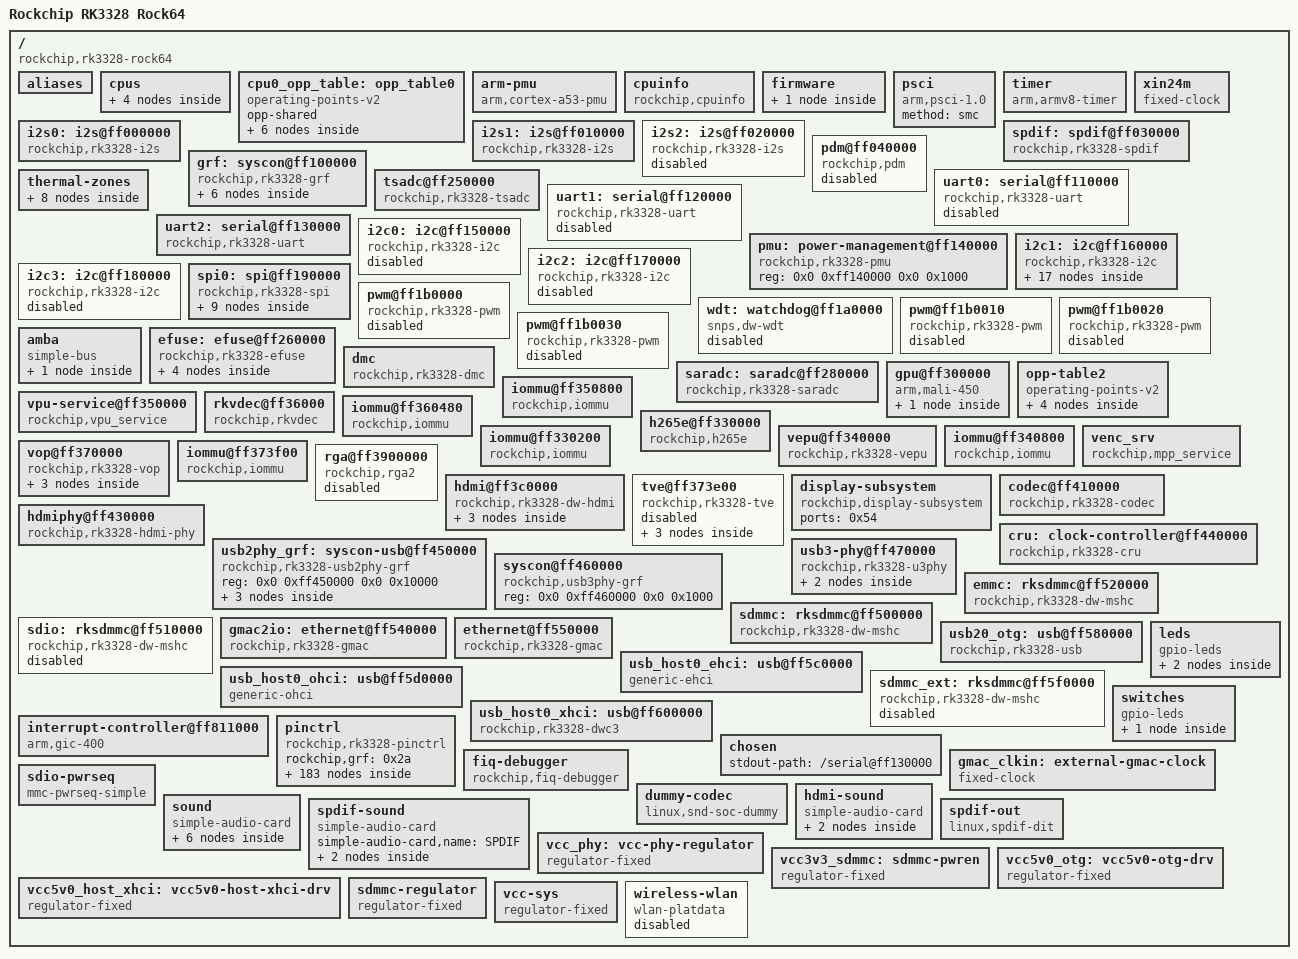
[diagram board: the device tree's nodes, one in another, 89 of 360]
/*
 * (C) Copyright 2017 Rock64
 *
 * SPDX-License-Identifier:     GPL-2.0+
 */

/dts-v1/;

#include <dt-bindings/clock/rk3328-cru.h>
#include <dt-bindings/gpio/gpio.h>
#include <dt-bindings/interrupt-controller/arm-gic.h>
#include <dt-bindings/interrupt-controller/irq.h>
#include <dt-bindings/pinctrl/rockchip.h>

/ {
	compatible = "rockchip,rk3328-rock64", "rockchip,rk3328";
	interrupt-parent = <0x1>;
	#address-cells = <0x2>;
	#size-cells = <0x2>;
	model = "Rockchip RK3328 Rock64";

	aliases {
		serial0 = &uart0;
		serial1 = &uart1;
		serial2 = &uart2;
		i2c0 = &i2c0;
		i2c1 = &i2c1;
		i2c2 = &i2c2;
		i2c3 = &i2c3;
		mmc0 = &emmc;
		mmc1 = &sdmmc;
		mmc2 = &sdmmc_ext;
		spi0 = &spi0;		
		ethernet0 = &gmac2io;
		ethernet1 = "/ethernet@ff550000";		
	};

	cpus {
		#address-cells = <2>;
		#size-cells = <0>;

		cpu0: cpu@0 {
			device_type = "cpu";
			compatible = "arm,cortex-a53", "arm,armv8";
			reg = <0x0 0x0>;
			enable-method = "psci";
			clocks = <&cru ARMCLK>;
			#cooling-cells = <0x2>;			
            dynamic-power-coefficient = <0x78>;
			operating-points-v2 = <&cpu0_opp_table>;			
			cpu-supply = <0x4>;
		};
		cpu1: cpu@1 {
			device_type = "cpu";
			compatible = "arm,cortex-a53", "arm,armv8";
			reg = <0x0 0x1>;
			enable-method = "psci";
			operating-points-v2 = <&cpu0_opp_table>;			
		};
		cpu2: cpu@2 {
			device_type = "cpu";
			compatible = "arm,cortex-a53", "arm,armv8";
			reg = <0x0 0x2>;
			enable-method = "psci";
			operating-points-v2 = <&cpu0_opp_table>;			
		};
		cpu3: cpu@3 {
			device_type = "cpu";
			compatible = "arm,cortex-a53", "arm,armv8";
			reg = <0x0 0x3>;
			enable-method = "psci";
			operating-points-v2 = <&cpu0_opp_table>;			
		};
	};

	cpu0_opp_table: opp_table0 {
		compatible = "operating-points-v2";
		opp-shared;

		opp@408000000 {
			opp-hz = /bits/ 64 <408000000>;
			opp-microvolt = <950000>;
			clock-latency-ns = <40000>;
			opp-suspend;
		};
		opp@600000000 {
			opp-hz = /bits/ 64 <600000000>;
			opp-microvolt = <950000>;
			clock-latency-ns = <40000>;
		};
		opp@816000000 {
			opp-hz = /bits/ 64 <816000000>;
			opp-microvolt = <1000000>;
			clock-latency-ns = <40000>;
		};
		opp@1008000000 {
			opp-hz = /bits/ 64 <1008000000>;
			opp-microvolt = <1100000>;
			clock-latency-ns = <40000>;
		};
		opp@1200000000 {
			opp-hz = /bits/ 64 <1200000000>;
			opp-microvolt = <1225000>;
			clock-latency-ns = <40000>;
		};
		opp@1296000000 {
			opp-hz = /bits/ 64 <1296000000>;
			opp-microvolt = <1300000>;
			clock-latency-ns = <40000>;
		};
	};

	arm-pmu {
		compatible = "arm,cortex-a53-pmu";
		interrupts = <GIC_SPI 100 IRQ_TYPE_LEVEL_HIGH>,
			     <GIC_SPI 101 IRQ_TYPE_LEVEL_HIGH>,
			     <GIC_SPI 102 IRQ_TYPE_LEVEL_HIGH>,
			     <GIC_SPI 103 IRQ_TYPE_LEVEL_HIGH>;
		interrupt-affinity = <&cpu0>, <&cpu1>, <&cpu2>, <&cpu3>;
	};

	cpuinfo {
		compatible = "rockchip,cpuinfo";
		nvmem-cells = <0x9 0xa>;
		nvmem-cell-names = "id", "cpu-version";
	};

	firmware {

		optee {
			compatible = "linaro,optee-tz";
			method = "smc";
		};
	};

	psci {
		compatible = "arm,psci-1.0";
		method = "smc";
	};

	timer {
		compatible = "arm,armv8-timer";
		interrupts = <GIC_PPI 13 (GIC_CPU_MASK_SIMPLE(4) | IRQ_TYPE_LEVEL_LOW)>,
			     <GIC_PPI 14 (GIC_CPU_MASK_SIMPLE(4) | IRQ_TYPE_LEVEL_LOW)>,
			     <GIC_PPI 11 (GIC_CPU_MASK_SIMPLE(4) | IRQ_TYPE_LEVEL_LOW)>,
			     <GIC_PPI 10 (GIC_CPU_MASK_SIMPLE(4) | IRQ_TYPE_LEVEL_LOW)>;
	};

	xin24m: xin24m {
		compatible = "fixed-clock";
		#clock-cells = <0>;
		clock-frequency = <24000000>;
		clock-output-names = "xin24m";
	};

	i2s0: i2s@ff000000 {
		compatible = "rockchip,rk3328-i2s", "rockchip,rk3066-i2s";
		reg = <0x0 0xff000000 0x0 0x1000>;
		interrupts = <GIC_SPI 26 IRQ_TYPE_LEVEL_HIGH>;
		clocks = <&cru SCLK_I2S0>, <&cru HCLK_I2S0_8CH>;
		clock-names = "i2s_clk", "i2s_hclk";
		dmas = <&dmac 11>, <&dmac 12>;
		#dma-cells = <2>;
		dma-names = "tx", "rx";
        status = "okay";
        #sound-dai-cells = <0x0>;
        rockchip,bclk-fs = <0x80>;

	};

	i2s1: i2s@ff010000 {
		compatible = "rockchip,rk3328-i2s", "rockchip,rk3066-i2s";
		reg = <0x0 0xff010000 0x0 0x1000>;
		interrupts = <GIC_SPI 27 IRQ_TYPE_LEVEL_HIGH>;
		clocks = <&cru SCLK_I2S1>, <&cru HCLK_I2S1_8CH>;
		clock-names = "i2s_clk", "i2s_hclk";
		dmas = <&dmac 14>, <&dmac 15>;
		#dma-cells = <2>;
		dma-names = "tx", "rx";
		status = "okay";
        pinctrl-names = "default";
        pinctrl-0 = <0xc 0xd 0xe 0xf 0x10 0x11 0x12 0x13 0x14>;
        #sound-dai-cells = <0x0>;

	};

	i2s2: i2s@ff020000 {
		compatible = "rockchip,rk3328-i2s", "rockchip,rk3066-i2s";
		reg = <0x0 0xff020000 0x0 0x1000>;
		interrupts = <GIC_SPI 28 IRQ_TYPE_LEVEL_HIGH>;
		clocks = <&cru SCLK_I2S2>, <&cru HCLK_I2S2_2CH>;
		clock-names = "i2s_clk", "i2s_hclk";
		dmas = <&dmac 0>, <&dmac 1>;
		#dma-cells = <2>;
		dma-names = "tx", "rx";
		pinctrl-names = "default", "sleep";
		pinctrl-0 = <&i2s2m0_mclk
			     &i2s2m0_sclk
			     &i2s2m0_lrcktx
			     &i2s2m0_lrckrx
			     &i2s2m0_sdo
			     &i2s2m0_sdi>;
		pinctrl-1 = <&i2s2m0_sleep>;
		status = "disabled";
	};

	spdif: spdif@ff030000 {
		compatible = "rockchip,rk3328-spdif";
		reg = <0x0 0xff030000 0x0 0x1000>;
		interrupts = <GIC_SPI 29 IRQ_TYPE_LEVEL_HIGH>;
		clocks = <&cru SCLK_SPDIF>, <&cru HCLK_SPDIF_8CH>;
		clock-names = "mclk", "hclk";
		dmas = <&dmac 10>;
		#dma-cells = <1>;
		dma-names = "tx";
		pinctrl-names = "default";
		pinctrl-0 = <&spdifm2_tx>;
		status = "okay";
        #sound-dai-cells = <0x0>;

	};

	pdm@ff040000 {
		compatible = "rockchip,pdm";
		reg = <0x0 0xff040000 0x0 0x1000>;
		clocks = <0x2 0x3d 0x2 0x152>;
		clock-names = "pdm_clk", "pdm_hclk";
		dmas = <0xb 0x10>;
		#dma-cells = <0x1>;
		dma-names = "rx";
		pinctrl-names = "default", "sleep";
		pinctrl-0 = <0x1d 0x1e 0x1f 0x20 0x21 0x22>;
		pinctrl-1 = <0x23>;
		status = "disabled";
	};

	grf: syscon@ff100000 {
		u-boot,dm-pre-reloc;
		compatible = "rockchip,rk3328-grf", "syscon", "simple-mfd";
		reg = <0x0 0xff100000 0x0 0x1000>;
		#address-cells = <0x1>;
		#size-cells = <0x1>;
		linux,phandle = <0x2a>;
		phandle = <0x2a>;

		io-domains {
			compatible = "rockchip,rk3328-io-voltage-domain";
			status = "okay";
			vccio1-supply = <0x24>;
			vccio2-supply = <0x25>;
			vccio3-supply = <0x24>;
			vccio4-supply = <0x26>;
			vccio5-supply = <0x24>;
			vccio6-supply = <0x24>;
			pmuio-supply = <0x24>;
		};

		power-controller {
			compatible = "rockchip,rk3328-power-controller";
			#power-domain-cells = <0x1>;
			#address-cells = <0x1>;
			#size-cells = <0x0>;
			status = "okay";
			linux,phandle = <0x45>;
			phandle = <0x45>;

			pd_hevc@6 {
				reg = <0x6>;
			};

			pd_video@5 {
				reg = <0x5>;
			};

			pd_vpu@8 {
				reg = <0x8>;
			};
		};

		reboot-mode {
			compatible = "syscon-reboot-mode";
			offset = <0x5c8>;
			mode-bootloader = <0x5242c301>;
			mode-charge = <0x5242c30b>;
			mode-fastboot = <0x5242c309>;
			mode-loader = <0x5242c301>;
			mode-normal = <0x5242c300>;
			mode-recovery = <0x5242c303>;
			mode-ums = <0x5242c30c>;
		};
	};

	thermal-zones {

		soc-thermal {
			polling-delay-passive = <0x14>;
			polling-delay = <0x3e8>;
			sustainable-power = <0x3e8>;
			thermal-sensors = <0x27 0x0>;

			trips {

				trip-point@0 {
					temperature = <0x11170>;
					hysteresis = <0x7d0>;
					type = "passive";
				};

				trip-point@1 {
					temperature = <0x14c08>;
					hysteresis = <0x7d0>;
					type = "passive";
					linux,phandle = <0x28>;
					phandle = <0x28>;
				};

				soc-crit {
					temperature = <0x17318>;
					hysteresis = <0x7d0>;
					type = "critical";
				};
			};

			cooling-maps {

				map0 {
					trip = <0x28>;
					cooling-device = <0x5 0xffffffff 0xffffffff>;
					contribution = <0x1000>;
				};

				map1 {
					trip = <0x28>;
					cooling-device = <0x29 0xffffffff 0xffffffff>;
					contribution = <0x1000>;
				};
			};
		};
	};

	tsadc@ff250000 {
		compatible = "rockchip,rk3328-tsadc";
		reg = <0x0 0xff250000 0x0 0x100>;
		interrupts = <0x0 0x3a 0x4 0x0>;
		rockchip,grf = <0x2a>;
		clocks = <0x2 0x24 0x2 0xd5>;
		clock-names = "tsadc", "apb_pclk";
		assigned-clocks = <0x2 0x24>;
		assigned-clock-rates = <0xc350>;
		resets = <0x2 0x42>;
		reset-names = "tsadc-apb";
		pinctrl-names = "init", "default", "sleep";
		pinctrl-0 = <0x2b>;
		pinctrl-1 = <0x2c>;
		pinctrl-2 = <0x2b>;
		#thermal-sensor-cells = <0x1>;
		rockchip,hw-tshut-temp = <0x186a0>;
		status = "okay";
		linux,phandle = <0x27>;
		phandle = <0x27>;
	};

	uart0: serial@ff110000 {
		compatible = "rockchip,rk3328-uart", "snps,dw-apb-uart";
		reg = <0x0 0xff110000 0x0 0x100>;
		interrupts = <GIC_SPI 55 IRQ_TYPE_LEVEL_HIGH>;
		clocks = <&cru SCLK_UART0>, <&cru PCLK_UART0>;
		clock-names = "baudclk", "apb_pclk";
		reg-shift = <2>;
		reg-io-width = <4>;
		dmas = <&dmac 2>, <&dmac 3>;
		#dma-cells = <2>;
		pinctrl-names = "default";
		pinctrl-0 = <&uart0_xfer &uart0_cts &uart0_rts>;
		status = "disabled";
	};

	uart1: serial@ff120000 {
		compatible = "rockchip,rk3328-uart", "snps,dw-apb-uart";
		reg = <0x0 0xff120000 0x0 0x100>;
		interrupts = <GIC_SPI 56 IRQ_TYPE_LEVEL_HIGH>;
		clocks = <&cru SCLK_UART1>, <&cru PCLK_UART1>;
		clock-names = "sclk_uart", "pclk_uart";
		reg-shift = <2>;
		reg-io-width = <4>;
		dmas = <&dmac 4>, <&dmac 5>;
		#dma-cells = <2>;
		pinctrl-names = "default";
		pinctrl-0 = <&uart1_xfer &uart1_cts &uart1_rts>;
		status = "disabled";
	};

	uart2: serial@ff130000 {
		u-boot,dm-pre-reloc;
		compatible = "rockchip,rk3328-uart", "snps,dw-apb-uart";
		reg = <0x0 0xff130000 0x0 0x100>;
		interrupts = <GIC_SPI 57 IRQ_TYPE_LEVEL_HIGH>;
		clocks = <&cru SCLK_UART2>, <&cru PCLK_UART2>;
		clock-names = "baudclk", "apb_pclk";
		clock-frequency = <24000000>;
		reg-shift = <2>;
		reg-io-width = <4>;
		dmas = <&dmac 6>, <&dmac 7>;
		#dma-cells = <2>;
		pinctrl-names = "default";
		pinctrl-0 = <&uart2m1_xfer>;
		status = "okay";
	};

	pmu: power-management@ff140000 {
		compatible = "rockchip,rk3328-pmu", "syscon", "simple-mfd";
		reg = <0x0 0xff140000 0x0 0x1000>;
	};

	i2c0: i2c@ff150000 {
		compatible = "rockchip,rk3328-i2c";
		reg = <0x0 0xff150000 0x0 0x1000>;
		interrupts = <GIC_SPI 36 IRQ_TYPE_LEVEL_HIGH>;
		#address-cells = <1>;
		#size-cells = <0>;
		clocks = <&cru SCLK_I2C0>, <&cru PCLK_I2C0>;
		clock-names = "i2c", "pclk";
		pinctrl-names = "default";
		pinctrl-0 = <&i2c0_xfer>;
		status = "disabled";
	};

	i2c1: i2c@ff160000 {
		compatible = "rockchip,rk3328-i2c";
		reg = <0x0 0xff160000 0x0 0x1000>;
		interrupts = <GIC_SPI 37 IRQ_TYPE_LEVEL_HIGH>;
		#address-cells = <1>;
		#size-cells = <0>;
		clocks = <&cru SCLK_I2C1>, <&cru PCLK_I2C1>;
		clock-names = "i2c", "pclk";
		pinctrl-names = "default";
		pinctrl-0 = <&i2c1_xfer>;
		clock-frequency = <400000>;
		i2c-scl-rising-time-ns = <168>;
		i2c-scl-falling-time-ns = <4>;
		status = "okay";

		rk805: pmic@18 {
			compatible = "rockchip,rk805";
			status = "okay";
			reg = <0x18>;
			interrupt-parent = <&gpio2>;
			interrupts = <6 IRQ_TYPE_LEVEL_LOW>;
			pinctrl-names = "default";
			pinctrl-0 = <&pmic_int_l>;
			rockchip,system-power-controller;
			wakeup-source;
			gpio-controller;
			#gpio-cells = <2>;
			#clock-cells = <1>;
			clock-output-names = "xin32k", "rk805-clkout2";

			pwrkey {
				status = "okay";
			};

			regulators {
				vdd_logic: DCDC_REG1 {
					regulator-name = "vdd_logic";
					regulator-min-microvolt = <712500>;
					regulator-max-microvolt = <1450000>;
					regulator-ramp-delay = <6001>;
					regulator-boot-on;
					regulator-always-on;
					regulator-state-mem {
						regulator-on-in-suspend;
						regulator-suspend-microvolt = <1000000>;
					};
				};

				vdd_arm: DCDC_REG2 {
					regulator-name = "vdd_arm";
					regulator-min-microvolt = <712500>;
					regulator-max-microvolt = <1450000>;
					regulator-ramp-delay = <6001>;
					regulator-boot-on;
					regulator-always-on;
					regulator-state-mem {
						regulator-on-in-suspend;
						regulator-suspend-microvolt = <1000000>;
					};
				};

				vcc_ddr: DCDC_REG3 {
					regulator-name = "vcc_ddr";
					regulator-boot-on;
					regulator-always-on;
					regulator-state-mem {
						regulator-on-in-suspend;
					};
				};

				vcc_io: DCDC_REG4 {
					regulator-name = "vcc_io";
					regulator-min-microvolt = <3300000>;
					regulator-max-microvolt = <3300000>;
					regulator-boot-on;
					regulator-always-on;
					regulator-state-mem {
						regulator-on-in-suspend;
						regulator-suspend-microvolt = <3300000>;
					};
				};

				vdd_18: LDO_REG1 {
					regulator-name = "vdd_18";
					regulator-min-microvolt = <1800000>;
					regulator-max-microvolt = <1800000>;
					regulator-boot-on;
					regulator-always-on;
					regulator-state-mem {
						regulator-on-in-suspend;
						regulator-suspend-microvolt = <1800000>;
					};
				};

				vcc_18emmc: LDO_REG2 {
					regulator-name = "vcc_18emmc";
					regulator-min-microvolt = <1800000>;
					regulator-max-microvolt = <1800000>;
					regulator-boot-on;
					regulator-always-on;
					regulator-state-mem {
						regulator-on-in-suspend;
						regulator-suspend-microvolt = <1800000>;
					};
				};

				vdd_10: LDO_REG3 {
					regulator-name = "vdd_10";
					regulator-min-microvolt = <1000000>;
					regulator-max-microvolt = <1000000>;
					regulator-boot-on;
					regulator-always-on;
					regulator-state-mem {
						regulator-on-in-suspend;
						regulator-suspend-microvolt = <1000000>;
					};
				};
			};
		};
	};

	i2c2: i2c@ff170000 {
		compatible = "rockchip,rk3328-i2c";
		reg = <0x0 0xff170000 0x0 0x1000>;
		interrupts = <GIC_SPI 38 IRQ_TYPE_LEVEL_HIGH>;
		#address-cells = <1>;
		#size-cells = <0>;
		clocks = <&cru SCLK_I2C2>, <&cru PCLK_I2C2>;
		clock-names = "i2c", "pclk";
		pinctrl-names = "default";
		pinctrl-0 = <&i2c2_xfer>;
		status = "disabled";
	};

	i2c3: i2c@ff180000 {
		compatible = "rockchip,rk3328-i2c";
		reg = <0x0 0xff180000 0x0 0x1000>;
		interrupts = <GIC_SPI 39 IRQ_TYPE_LEVEL_HIGH>;
		#address-cells = <1>;
		#size-cells = <0>;
		clocks = <&cru SCLK_I2C3>, <&cru PCLK_I2C3>;
		clock-names = "i2c", "pclk";
		pinctrl-names = "default";
		pinctrl-0 = <&i2c3_xfer>;
		status = "disabled";
	};

	spi0: spi@ff190000 {
		u-boot,dm-spl;
		compatible = "rockchip,rk3328-spi";
		reg = <0x0 0xff190000 0x0 0x1000>;
		interrupts = <GIC_SPI 49 IRQ_TYPE_LEVEL_HIGH>;
		#address-cells = <1>;
		#size-cells = <0>;
		clocks = <&cru SCLK_SPI>, <&cru PCLK_SPI>;
		clock-names = "spiclk", "apb_pclk";
		dmas = <&dmac 8>, <&dmac 9>;
		#dma-cells = <2>;
		dma-names = "tx", "rx";
		pinctrl-names = "default";
		pinctrl-0 = <&spi0m2_clk &spi0m2_tx &spi0m2_rx &spi0m2_cs0>;
		status = "okay";

		gd25q128@0 {
			u-boot,dm-spl;
			#address-cells = <0x1>;
			#size-cells = <0x0>;
			compatible = "jedec,spi-nor";
			reg = <0x0>;
			spi-max-frequency = <104000000>;
			status = "okay";

			partitions {
				compatible = "fixed-partitions";
				#address-cells = <0x1>;
				#size-cells = <0x1>;

				mbr@0 {
					label = "mbr";
					reg = <0x0 0x200>;
					read-only;
				};
				
				primarygpt@200 {
					label = "primarygpt";
					reg = <0x200 0x7E00>;
					read-only;
				};
				
				loader1@8000 {
					label = "loader1";
					reg = <0x8000 0x3E8000>;					
				};

				reserved1@3F0000 {
					label = "reserved1";
					reg = <0x3F0000 0x10000>;
					read-only;
				};

				reserved2@400000 {
					label = "reserved2";
					reg = <0x400000 0x400000>;
					read-only;
				};

				loader2@800000 {
					label = "loader2";
					reg = <0x800000 0x400000>;
				};

				atf@C00000 {
					label = "atf";
					reg = <0xC00000 0x400000>;
					read-only;
				};
			};
		};
	};	
		
	wdt: watchdog@ff1a0000 {
		compatible = "snps,dw-wdt";
		reg = <0x0 0xff1a0000 0x0 0x100>;
		interrupts = <GIC_SPI 40 IRQ_TYPE_LEVEL_HIGH>;
		status = "disabled";
	};

	pwm@ff1b0000 {
		compatible = "rockchip,rk3328-pwm";
		reg = <0x0 0xff1b0000 0x0 0x10>;
		#pwm-cells = <0x3>;
		pinctrl-names = "default";
		pinctrl-0 = <0x3e>;
		clocks = <0x2 0x3c 0x2 0xd6>;
		clock-names = "pwm", "pclk";
		status = "disabled";
	};

	pwm@ff1b0010 {
		compatible = "rockchip,rk3328-pwm";
		reg = <0x0 0xff1b0010 0x0 0x10>;
		#pwm-cells = <0x3>;
		pinctrl-names = "default";
		pinctrl-0 = <0x3f>;
		clocks = <0x2 0x3c 0x2 0xd6>;
		clock-names = "pwm", "pclk";
		status = "disabled";
	};

	pwm@ff1b0020 {
		compatible = "rockchip,rk3328-pwm";
		reg = <0x0 0xff1b0020 0x0 0x10>;
		#pwm-cells = <0x3>;
		pinctrl-names = "default";
		pinctrl-0 = <0x40>;
		clocks = <0x2 0x3c 0x2 0xd6>;
		clock-names = "pwm", "pclk";
		status = "disabled";
	};

	pwm@ff1b0030 {
		compatible = "rockchip,rk3328-pwm";
		reg = <0x0 0xff1b0030 0x0 0x10>;
		interrupts = <0x0 0x32 0x4>;
		#pwm-cells = <0x3>;
		pinctrl-names = "default";
		pinctrl-0 = <0x41>;
		clocks = <0x2 0x3c 0x2 0xd6>;
		clock-names = "pwm", "pclk";
		status = "disabled";
	};

	amba {
		compatible = "simple-bus";
		#address-cells = <0x2>;
		#size-cells = <0x2>;
		ranges;

		dmac: dmac@ff1f0000 {
			compatible = "arm,pl330", "arm,primecell";
			reg = <0x0 0xff1f0000 0x0 0x4000>;
			interrupts = <GIC_SPI 0 IRQ_TYPE_LEVEL_HIGH>,
				     <GIC_SPI 1 IRQ_TYPE_LEVEL_HIGH>;
			clocks = <&cru ACLK_DMAC>;
			clock-names = "apb_pclk";
			#dma-cells = <0x1>;
			peripherals-req-type-burst;
			linux,phandle = <0xb>;
			phandle = <0xb>;
		};
	};
	
	efuse: efuse@ff260000 {
		compatible = "rockchip,rk3328-efuse";
		reg = <0x0 0xff260000 0x0 0x50>;
		#address-cells = <0x1>;
		#size-cells = <0x1>;
		clocks = <&cru SCLK_EFUSE>;
		clock-names = "pclk_efuse";
		rockchip,efuse-size = <0x20>;

		efuse_id: id@7 {
			reg = <0x7 0x10>;
			linux,phandle = <0x9>;
			phandle = <0x9>;
		};

		cpu_leakage: cpu-leakage@17 {
			reg = <0x17 0x1>;
		};

		logic_leakage: logic-leakage@19 {
			reg = <0x19 0x1>;
		};

		efuse_cpu_version: cpu-version@1a {
			reg = <0x1a 0x1>;
			bits = <0x3 0x3>;
			linux,phandle = <0xa>;
			phandle = <0xa>;
		};
	};

	saradc: saradc@ff280000 {
		compatible = "rockchip,rk3328-saradc", "rockchip,rk3399-saradc";
		reg = <0x0 0xff280000 0x0 0x100>;
		interrupts = <GIC_SPI 80 IRQ_TYPE_LEVEL_HIGH>;
		#io-channel-cells = <0x1>;
		clocks = <&cru SCLK_SARADC>, <&cru PCLK_SARADC>;
		clock-names = "saradc", "apb_pclk";
		resets = <&cru SRST_SARADC_P>;
		reset-names = "saradc-apb";
		status = "okay";
	};
	
	dmc: dmc {
		u-boot,dm-pre-reloc;
		compatible = "rockchip,rk3328-dmc";
		reg = <0x0 0xff400000 0x0 0x1000
		       0x0 0xff780000 0x0 0x3000
		       0x0 0xff100000 0x0 0x1000
		       0x0 0xff440000 0x0 0x1000
		       0x0 0xff720000 0x0 0x1000
		       0x0 0xff798000 0x0 0x1000>;
	};
	

	gpu@ff300000 {
		compatible = "arm,mali-450";
		reg = <0x0 0xff300000 0x0 0x40000 0x0 0xff300000 0x0 0x40000>;
		interrupts = <0x0 0x5a 0x4 0x0 0x57 0x4 0x0 0x5d 0x4 0x0 0x58 0x4 0x0 0x59 0x4 0x0 0x5b 0x4 0x0 0x5c 0x4>;
		interrupt-names = "Mali_GP_IRQ", "Mali_GP_MMU_IRQ", "IRQPP", "Mali_PP0_IRQ", "Mali_PP0_MMU_IRQ", "Mali_PP1_IRQ", "Mali_PP1_MMU_IRQ";
		clocks = <0x2 0x87>;
		clock-names = "clk_mali";
		#cooling-cells = <0x2>;
		operating-points-v2 = <0x42>;
		status = "okay";
		mali-supply = <0x43>;
		linux,phandle = <0x29>;
		phandle = <0x29>;

		power_model {
			compatible = "arm,mali-simple-power-model";
			voltage = <0x384>;
			frequency = <0x1f4>;
			static-power = <0x12c>;
			dynamic-power = <0x18c>;
			ts = <0x7d00 0x125c 0xffffffb0 0x2>;
			thermal-zone = "soc-thermal";
		};
	};

	opp-table2 {
		compatible = "operating-points-v2";
		linux,phandle = <0x42>;
		phandle = <0x42>;

		opp-200000000 {
			opp-hz = <0x0 0xbebc200>;
			opp-microvolt = <0x100590>;
		};

		opp-300000000 {
			opp-hz = <0x0 0x11e1a300>;
			opp-microvolt = <0x100590>;
		};

		opp-400000000 {
			opp-hz = <0x0 0x17d78400>;
			opp-microvolt = <0x100590>;
		};

		opp-500000000 {
			opp-hz = <0x0 0x1dcd6500>;
			opp-microvolt = <0x10c8e0>;
		};
	};

	vpu-service@ff350000 {
		compatible = "rockchip,vpu_service";
		reg = <0x0 0xff350000 0x0 0x800>;
		interrupts = <0x0 0x9 0x4>;
		interrupt-names = "irq_dec";
		resets = <0x2 0xa0 0x2 0xa2>;
		reset-names = "video_a", "video_h";
		clocks = <0x2 0x8f 0x2 0x146>;
		clock-names = "aclk_vcodec", "hclk_vcodec";
		rockchip,grf = <0x2a>;
		iommus = <0x44>;
		allocator = <0x1>;
		power-domains = <0x45 0x8>;
		status = "okay";
	};

	iommu@ff350800 {
		compatible = "rockchip,iommu";
		reg = <0x0 0xff350800 0x0 0x40>;
		interrupts = <0x0 0xb 0x4>;
		interrupt-names = "vpu_mmu";
		clock-names = "aclk", "hclk";
		clocks = <0x2 0x8f 0x2 0x146>;
		power-domains = <0x45 0x8>;
		#iommu-cells = <0x0>;
		linux,phandle = <0x44>;
		phandle = <0x44>;
	};

	rkvdec@ff36000 {
		compatible = "rockchip,rkvdec";
		reg = <0x0 0xff360000 0x0 0x400>;
		interrupts = <0x0 0x7 0x4>;
		interrupt-names = "irq_dec";
		clocks = <0x2 0x8b 0x2 0x142 0x2 0x41 0x2 0x42>;
		clock-names = "aclk_vcodec", "hclk_vcodec", "clk_cabac", "clk_core";
		resets = <0x2 0xa4 0x2 0xa6 0x2 0xa5 0x2 0xa7 0x2 0xa9 0x2 0xa8>;
		reset-names = "video_a", "video_h", "niu_a", "niu_h", "cabac", "video";
		rockchip,grf = <0x2a>;
		iommus = <0x46>;
		allocator = <0x1>;
		power-domains = <0x45 0x5>;
		status = "okay";
	};

	iommu@ff360480 {
		compatible = "rockchip,iommu";
		reg = <0x0 0xff360480 0x0 0x40 0x0 0xff3604c0 0x0 0x40>;
		interrupts = <0x0 0x4a 0x4>;
		interrupt-names = "rkvdec_mmu";
		clocks = <0x2 0x8b 0x2 0x142>;
		clock-names = "aclk_vcodec", "hclk_vcodec";
		power-domains = <0x45 0x5>;
		#iommu-cells = <0x0>;
		linux,phandle = <0x46>;
		phandle = <0x46>;
	};

	h265e@ff330000 {
		compatible = "rockchip,h265e";
		rockchip,grf = <0x2a>;
		iommu_enabled = <0x1>;
		iommus = <0x47>;
		reg = <0x0 0xff330000 0x0 0x200>;
		interrupts = <0x0 0x5f 0x4>;
		clocks = <0x2 0x93 0x2 0xdd 0x2 0x44 0x2 0x43 0x2 0x8c 0x2 0x82>;
		clock-names = "aclk_h265", "pclk_h265", "clk_core", "clk_dsp", "aclk_venc", "aclk_axi2sram";
		rockchip,srv = <0x48>;
		mode_bit = <0xb>;
		mode_ctrl = <0x40c>;
		allocator = <0x1>;
		power-domains = <0x45 0x6>;
		status = "okay";
	};

	iommu@ff330200 {
		compatible = "rockchip,iommu";
		reg = <0x0 0xff330200 0x0 0x100>;
		interrupts = <0x0 0x60 0x4>;
		interrupt-names = "h265e_mmu";
		power-domains = <0x45 0x6>;
		#iommu-cells = <0x0>;
		linux,phandle = <0x47>;
		phandle = <0x47>;
	};

	vepu@ff340000 {
		compatible = "rockchip,rk3328-vepu", "rockchip,vepu";
		rockchip,grf = <0x2a>;
		iommu_enabled = <0x1>;
		iommus = <0x49>;
		reg = <0x0 0xff340000 0x0 0x400>;
		interrupts = <0x0 0x61 0x4>;
		clocks = <0x2 0x94 0x2 0x14a 0x2 0x44>;
		clock-names = "aclk_vcodec", "hclk_vcodec", "clk_core";
		resets = <0x2 0xb7 0x2 0xb6>;
		reset-names = "video_h", "video_a";
		rockchip,srv = <0x48>;
		mode_bit = <0xb>;
		mode_ctrl = <0x40c>;
		allocator = <0x1>;
		power-domains = <0x45 0x6>;
		status = "okay";
	};

	iommu@ff340800 {
		compatible = "rockchip,iommu";
		reg = <0x0 0xff340800 0x0 0x40>;
		interrupts = <0x0 0x62 0x4>;
		interrupt-names = "vepu_mmu";
		clocks = <0x2 0x94 0x2 0x14a>;
		clock-names = "aclk", "hclk";
		power-domains = <0x45 0x6>;
		#iommu-cells = <0x0>;
		linux,phandle = <0x49>;
		phandle = <0x49>;
	};

	venc_srv {
		compatible = "rockchip,mpp_service";
		linux,phandle = <0x48>;
		phandle = <0x48>;
	};

	vop@ff370000 {
		compatible = "rockchip,rk3328-vop";
		reg = <0x0 0xff370000 0x0 0x3efc>;
		reg-names = "regs", "gamma_lut";
		interrupts = <0x0 0x20 0x4 0x0>;
		clocks = <0x2 0x91 0x2 0x78 0x2 0x13b>;
		clock-names = "aclk_vop", "dclk_vop", "hclk_vop";
		resets = <0x2 0x85 0x2 0x86 0x2 0x87>;
		reset-names = "axi", "ahb", "dclk";
		iommus = <0x4a>;
		status = "okay";

		port {
			#address-cells = <0x1>;
			#size-cells = <0x0>;
			linux,phandle = <0x54>;
			phandle = <0x54>;

			endpoint@0 {
				reg = <0x0>;
				remote-endpoint = <0x4b>;
				linux,phandle = <0x52>;
				phandle = <0x52>;
			};

			endpoint@1 {
				reg = <0x1>;
				remote-endpoint = <0x4c>;
				linux,phandle = <0x53>;
				phandle = <0x53>;
			};
		};
	};

	iommu@ff373f00 {
		compatible = "rockchip,iommu";
		reg = <0x0 0xff373f00 0x0 0x100>;
		interrupts = <0x0 0x20 0x4 0x0>;
		interrupt-names = "vop_mmu";
		#iommu-cells = <0x0>;
		status = "okay";
		linux,phandle = <0x4a>;
		phandle = <0x4a>;
	};

	rga@ff3900000 {
		compatible = "rockchip,rga2";
		dev_mode = <0x1>;
		reg = <0x0 0xff390000 0x0 0x1000>;
		interrupts = <0x0 0x21 0x4>;
		clocks = <0x2 0x9a 0x2 0x154 0x2 0x45>;
		clock-names = "aclk_rga", "hclk_rga", "clk_rga";
		dma-coherent;
		status = "disabled";
	};

	hdmi@ff3c0000 {
		compatible = "rockchip,rk3328-dw-hdmi";
		reg = <0x0 0xff3c0000 0x0 0x20000>;
		reg-io-width = <0x4>;
		interrupts = <0x0 0x23 0x4 0x0 0x47 0x4>;
		clocks = <0x2 0xe7 0x2 0x46 0x2 0x147>;
		clock-names = "iahb", "isfr", "hclk_vio";
		phys = <0x4d>;
		phy-names = "hdmi_phy";
		pinctrl-names = "default", "gpio";
		pinctrl-0 = <0x4e 0x4f 0x50>;
		pinctrl-1 = <0x51>;
		resets = <0x2 0x8f 0x2 0x51>;
		reset-names = "hdmi", "hdmiphy";
		rockchip,grf = <0x2a>;
		status = "okay";
		#sound-dai-cells = <0x0>;
		ddc-i2c-scl-high-time-ns = <0x2599>;
		ddc-i2c-scl-low-time-ns = <0x2710>;
		linux,phandle = <0x7d>;
		phandle = <0x7d>;

		ports {

			port {
				#address-cells = <0x1>;
				#size-cells = <0x0>;

				endpoint@0 {
					reg = <0x0>;
					remote-endpoint = <0x52>;
					linux,phandle = <0x4b>;
					phandle = <0x4b>;
				};
			};
		};
	};

	tve@ff373e00 {
		compatible = "rockchip,rk3328-tve";
		reg = <0x0 0xff373e00 0x0 0x100 0x0 0xff420000 0x0 0x10000>;
		rockchip,saturation = <0x376749>;
		rockchip,brightcontrast = <0xa305>;
		rockchip,adjtiming = <0xb6c00880>;
		rockchip,lumafilter0 = <0x1ff0000>;
		rockchip,lumafilter1 = <0xf40200fe>;
		rockchip,lumafilter2 = <0xf332d70c>;
		rockchip,daclevel = <0x22>;
		rockchip,dac1level = <0x7>;
		status = "disabled";

		ports {

			port {
				#address-cells = <0x1>;
				#size-cells = <0x0>;

				endpoint@0 {
					reg = <0x0>;
					remote-endpoint = <0x53>;
					linux,phandle = <0x4c>;
					phandle = <0x4c>;
				};
			};
		};
	};

	display-subsystem {
		compatible = "rockchip,display-subsystem";
		ports = <0x54>;
		status = "okay";
	};

	codec@ff410000 {
		compatible = "rockchip,rk3328-codec";
		reg = <0x0 0xff410000 0x0 0x1000>;
		rockchip,grf = <0x2a>;
		clocks = <0x2 0xeb>;
		clock-names = "pclk";
		status = "okay";
		#sound-dai-cells = <0x0>;
		linux,phandle = <0x7f>;
		phandle = <0x7f>;
	};

	hdmiphy@ff430000 {
		compatible = "rockchip,rk3328-hdmi-phy";
		reg = <0x0 0xff430000 0x0 0x10000>;
		interrupts = <0x0 0x53 0x4>;
		#phy-cells = <0x0>;
		clocks = <0x2 0xe4 0x55>;
		clock-names = "sysclk", "refclk";
		#clock-cells = <0x0>;
		clock-output-names = "hdmi_phy";
		status = "okay";
		linux,phandle = <0x4d>;
		phandle = <0x4d>;
	};

	cru: clock-controller@ff440000 {
		u-boot,dm-pre-reloc;
		compatible = "rockchip,rk3328-cru", "rockchip,cru", "syscon";
		reg = <0x0 0xff440000 0x0 0x1000>;
		rockchip,grf = <0x2a>;
		#clock-cells = <0x1>;
		#reset-cells = <0x1>;
		assigned-clocks =
			<&cru DCLK_LCDC>, <&cru SCLK_PDM>,
			<&cru SCLK_RTC32K>, <&cru SCLK_UART0>,
			<&cru SCLK_UART1>, <&cru SCLK_UART2>,
			<&cru ACLK_BUS_PRE>, <&cru ACLK_PERI_PRE>,
			<&cru ACLK_VIO_PRE>, <&cru ACLK_RGA_PRE>,
			<&cru ACLK_VOP_PRE>, <&cru ACLK_RKVDEC_PRE>,
			<&cru ACLK_RKVENC>, <&cru ACLK_VPU_PRE>,
			<&cru SCLK_VDEC_CABAC>, <&cru SCLK_VDEC_CORE>,
			<&cru SCLK_VENC_CORE>, <&cru SCLK_VENC_DSP>,
			<&cru SCLK_SDIO>, <&cru SCLK_TSP>,
			<&cru SCLK_WIFI>, <&cru ARMCLK>,
			<&cru PLL_GPLL>, <&cru PLL_CPLL>,
			<&cru ACLK_BUS_PRE>, <&cru HCLK_BUS_PRE>,
			<&cru PCLK_BUS_PRE>, <&cru ACLK_PERI_PRE>,
			<&cru HCLK_PERI>, <&cru PCLK_PERI>,
			<&cru ACLK_VIO_PRE>, <&cru HCLK_VIO_PRE>,
			<&cru ACLK_RGA_PRE>, <&cru SCLK_RGA>,
			<&cru ACLK_VOP_PRE>, <&cru ACLK_RKVDEC_PRE>,
			<&cru ACLK_RKVENC>, <&cru ACLK_VPU_PRE>,
			<&cru SCLK_VDEC_CABAC>, <&cru SCLK_VDEC_CORE>,
			<&cru SCLK_VENC_CORE>, <&cru SCLK_VENC_DSP>,
			<&cru SCLK_EFUSE>, <&cru PCLK_DDR>,
			<&cru ACLK_GMAC>, <&cru PCLK_GMAC>,
			<&cru SCLK_RTC32K>, <&cru SCLK_USB3OTG_SUSPEND>;
		assigned-clock-parents =
			<&cru HDMIPHY>, <&cru PLL_APLL>,
			<&cru PLL_GPLL>, <&xin24m>,
			<&xin24m>, <&xin24m>;
		assigned-clock-rates =
			<0>, <61440000>,
			<0>, <24000000>,
			<24000000>, <24000000>,
			<15000000>, <15000000>,
			<100000000>, <100000000>,
			<100000000>, <100000000>,
			<50000000>, <100000000>,
			<100000000>, <100000000>,
			<50000000>, <50000000>,
			<50000000>, <50000000>,
			<24000000>, <600000000>,
			<491520000>, <1200000000>,
			<150000000>, <75000000>,
			<75000000>, <150000000>,
			<75000000>, <75000000>,
			<300000000>, <100000000>,
			<300000000>, <200000000>,
			<400000000>, <500000000>,
			<200000000>, <300000000>,
			<300000000>, <250000000>,
			<200000000>, <100000000>,
			<24000000>, <100000000>,
			<150000000>, <50000000>,
			<32768>, <32768>;
		linux,phandle = <0x2>;
		phandle = <0x2>;
	};

	usb2phy_grf: syscon-usb@ff450000 {
		compatible = "rockchip,rk3328-usb2phy-grf", "syscon", "simple-mfd";
		reg = <0x0 0xff450000 0x0 0x10000>;
		#address-cells = <0x1>;
		#size-cells = <0x1>;

		u2phy: usb2-phy@100 {
			compatible = "rockchip,rk3328-usb2phy";
			reg = <0x100 0x10>;
			clocks = <&xin24m>;
			clock-names = "phyclk";
			#clock-cells = <0x0>;
			assigned-clocks = <&cru USB480M>;
			assigned-clock-parents = <&u2phy>;
			clock-output-names = "usb480m_phy";
			status = "okay";
			otg-vbus-gpios = <0x57 0x1b 0x0>;
			linux,phandle = <0x56>;
			phandle = <0x56>;

			u2phy_host: host-port {
				#phy-cells = <0x0>;
				interrupts = <GIC_SPI 59 IRQ_TYPE_LEVEL_HIGH>,
					     <GIC_SPI 60 IRQ_TYPE_LEVEL_HIGH>,
					     <GIC_SPI 61 IRQ_TYPE_LEVEL_HIGH>;
				interrupt-names = "linestate";
				status = "okay";
				linux,phandle = <0x6c>;
				phandle = <0x6c>;
			};

			u2phy_otg: otg-port {
				#phy-cells = <0x0>;
				interrupts = <GIC_SPI 62 IRQ_TYPE_LEVEL_HIGH>;
				interrupt-names = "otg-bvalid", "otg-id", "linestate";
				status = "okay";
				linux,phandle = <0x6b>;
				phandle = <0x6b>;
			};
		};
	};

	syscon@ff460000 {
		compatible = "rockchip,usb3phy-grf", "syscon";
		reg = <0x0 0xff460000 0x0 0x1000>;
		linux,phandle = <0x58>;
		phandle = <0x58>;
	};

	usb3-phy@ff470000 {
		compatible = "rockchip,rk3328-u3phy";
		reg = <0x0 0xff470000 0x0 0x0>;
		rockchip,u3phygrf = <0x58>;
		rockchip,grf = <0x2a>;
		interrupts = <0x0 0x4d 0x4>;
		interrupt-names = "linestate";
		clocks = <0x2 0xe0 0x2 0xe1>;
		clock-names = "u3phy-otg", "u3phy-pipe";
		resets = <0x2 0x7d 0x2 0x7e 0x2 0x7f 0x2 0x7c 0x2 0x9e 0x2 0x9f>;
		reset-names = "u3phy-u2-por", "u3phy-u3-por", "u3phy-pipe-mac", "u3phy-utmi-mac", "u3phy-utmi-apb", "u3phy-pipe-apb";
		#address-cells = <0x2>;
		#size-cells = <0x2>;
		ranges;
		status = "okay";
		vbus-drv-gpios = <0x57 0x0 0x0>;

		utmi@ff470000 {
			reg = <0x0 0xff470000 0x0 0x8000>;
			#phy-cells = <0x0>;
			status = "okay";
			linux,phandle = <0x6d>;
			phandle = <0x6d>;
		};

		pipe@ff478000 {
			reg = <0x0 0xff478000 0x0 0x8000>;
			#phy-cells = <0x0>;
			status = "okay";
			linux,phandle = <0x6e>;
			phandle = <0x6e>;
		};
	};

	emmc: rksdmmc@ff520000 {
		compatible = "rockchip,rk3328-dw-mshc", "rockchip,rk3288-dw-mshc";
		reg = <0x0 0xff520000 0x0 0x4000>;
		max-frequency = <150000000>;
		clocks = <&cru HCLK_EMMC>, <&cru SCLK_EMMC>;
		clock-names = "biu", "ciu", "ciu-drv", "ciu-sample";
		fifo-depth = <0x100>;
		interrupts = <GIC_SPI 14 IRQ_TYPE_LEVEL_HIGH>;
		status = "okay";
		u-boot,dm-spl;
		bus-width = <0x8>;
		cap-mmc-highspeed;
		supports-emmc;
		disable-wp;
		mmc-hs200-1_8v;
		non-removable;
		num-slots = <0x1>;
		pinctrl-names = "default";
		pinctrl-0 = <&emmc_clk &emmc_cmd &emmc_bus8>;
		vmmc-supply = <0x24>;
		vqmmc-supply = <0x25>;
	};

	sdmmc: rksdmmc@ff500000 {		
		compatible = "rockchip,rk3328-dw-mshc", "rockchip,rk3288-dw-mshc";
		reg = <0x0 0xff500000 0x0 0x4000>;
		max-frequency = <150000000>;
		clocks = <&cru HCLK_SDMMC>, <&cru SCLK_SDMMC>;
		clock-names = "biu", "ciu";
		fifo-depth = <0x100>;
		interrupts = <GIC_SPI 12 IRQ_TYPE_LEVEL_HIGH>;
		status = "okay";
		u-boot,dm-spl;
		bus-width = <0x4>;
		cap-mmc-highspeed;
		cap-sd-highspeed;
		fifo-mode;
		card-detect-delay = <200>;
		cd-gpios = <0x5c 0x5 0x1>;
		disable-wp;
		num-slots = <0x1>;
		pinctrl-names = "default";
		pinctrl-0 = <&sdmmc0_clk>, <&sdmmc0_cmd>, <&sdmmc0_dectn>, <&sdmmc0_bus4>;
		supports-sd;
		vmmc-supply = <0x61>;
		vqmmc-supply = <0x61>;
	};

	sdio: rksdmmc@ff510000 {
		compatible = "rockchip,rk3328-dw-mshc", "rockchip,rk3288-dw-mshc";
		reg = <0x0 0xff510000 0x0 0x4000>;
		max-frequency = <150000000>;
		clocks = <&cru HCLK_SDIO>, <&cru SCLK_SDIO>,
			 <&cru SCLK_SDIO_DRV>, <&cru SCLK_SDIO_SAMPLE>;
		clock-names = "biu", "ciu", "ciu-drv", "ciu-sample";
		fifo-depth = <0x100>;
		interrupts = <GIC_SPI 13 IRQ_TYPE_LEVEL_HIGH>;
		status = "disabled";
		bus-width = <0x4>;
		cap-sd-highspeed;
		cap-sdio-irq;
		disable-wp;
		keep-power-in-suspend;
		mmc-pwrseq = <0x62>;
		non-removable;
		num-slots = <0x1>;
		pinctrl-names = "default";
		pinctrl-0 = <0x63 0x64 0x65>;
		supports-sdio;
	};

	gmac2io: ethernet@ff540000 {
		compatible = "rockchip,rk3328-gmac";
		reg = <0x0 0xff540000 0x0 0x10000>;
		rockchip,grf = <&grf>;
		interrupts = <GIC_SPI 24 IRQ_TYPE_LEVEL_HIGH>;
		interrupt-names = "macirq";
		clocks = <&cru SCLK_MAC2IO>, <&cru SCLK_MAC2IO_RX>,
			 <&cru SCLK_MAC2IO_TX>, <&cru SCLK_MAC2IO_REF>,
			 <&cru SCLK_MAC2IO_REFOUT>, <&cru ACLK_MAC2IO>,
			 <&cru PCLK_MAC2IO>;
		clock-names = "stmmaceth", "mac_clk_rx", "mac_clk_tx", "clk_mac_ref", "clk_mac_refout", "aclk_mac", "pclk_mac";
		resets = <&cru SRST_GMAC2IO_A>;
		reset-names = "stmmaceth";
		status = "okay";
		phy-supply = <&vcc_phy>;
		phy-mode = "rgmii";
		clock_in_out = "input";
		snps,reset-gpio = <&gpio1 RK_PC2 GPIO_ACTIVE_LOW>;
		snps,reset-active-low;
		snps,reset-delays-us = <0 10000 50000>;
		assigned-clocks = <&cru SCLK_MAC2IO>, <&cru SCLK_MAC2IO_EXT>;
		assigned-clock-parents = <&gmac_clkin>, <&gmac_clkin>;
		pinctrl-names = "default";
		pinctrl-0 = <&rgmiim1_pins>;
		max-speed = <100>;
		tx_delay = <0x26>;
		rx_delay = <0x11>;
		status = "okay";
	};

	ethernet@ff550000 {
		compatible = "rockchip,rk3328-gmac";
		reg = <0x0 0xff550000 0x0 0x10000>;
		rockchip,grf = <0x2a>;
		interrupts = <0x0 0x15 0x4>;
		interrupt-names = "macirq";
		clocks = <0x2 0x54 0x2 0x53 0x2 0x53 0x2 0x55 0x2 0x95 0x2 0xde 0x2 0x56>;
		clock-names = "stmmaceth", "mac_clk_rx", "mac_clk_tx", "clk_mac_ref", "aclk_mac", "pclk_mac", "clk_macphy";
		resets = <0x2 0x62 0x2 0x64>;
		reset-names = "stmmaceth", "mac-phy";
		phy-mode = "rmii";
		phy-is-integrated;
		pinctrl-names = "default";
		pinctrl-0 = <0x69 0x6a>;
		status = "okay";
		phy-supply = <0x66>;
		clock_in_out = "output";
		assigned-clocks = <0x2 0x65>;
		assigned-clock-rate = <0x2faf080>;
		assigned-clock-parents = <0x2 0x54>;
	};

	usb20_otg: usb@ff580000 {
		compatible = "rockchip,rk3328-usb", "rockchip,rk3066-usb", "snps,dwc2";
		reg = <0x0 0xff580000 0x0 0x40000>;
		interrupts = <GIC_SPI 23 IRQ_TYPE_LEVEL_HIGH>;
		clocks = <0x2 0x14d 0x2 0x14c>;
		clock-names = "otg", "otg_pmu";
		dr_mode = "host";
		g-np-tx-fifo-size = <0x10>;
		g-rx-fifo-size = <0x113>;
		g-tx-fifo-size = <0x100 0x80 0x80 0x40 0x40 0x20>;
		g-use-dma;
		phys = <&u2phy 0>;
		phy-names = "usb2-phy";
		status = "okay";
		vbus-supply = <&vcc5v0_otg>;
	};

	usb_host0_ehci: usb@ff5c0000 {
		compatible = "generic-ehci";
		reg = <0x0 0xff5c0000 0x0 0x10000>;
		interrupts = <GIC_SPI 16 IRQ_TYPE_LEVEL_HIGH>;
		clocks = <0x2 0x14e 0x2 0x14f 0x56>;
		clock-names = "usbhost", "arbiter", "utmi";
		phys = <&u2phy 1>;
		phy-names = "usb";
		status = "okay";
	};

	usb_host0_ohci: usb@ff5d0000 {
		compatible = "generic-ohci";
		reg = <0x0 0xff5d0000 0x0 0x10000>;
		interrupts = <GIC_SPI 17 IRQ_TYPE_LEVEL_HIGH>;
		clocks = <0x2 0x14e 0x2 0x14f 0x56>;
		clock-names = "usbhost", "arbiter", "utmi";
		phys = <&u2phy 1>;
		phy-names = "usb";
		status = "okay";
	};

	sdmmc_ext: rksdmmc@ff5f0000 {
		compatible = "rockchip,rk3328-dw-mshc", "rockchip,rk3288-dw-mshc";
		reg = <0x0 0xff5f0000 0x0 0x4000>;
		max-frequency = <150000000>;
		clocks = <&cru HCLK_SDMMC>, <&cru SCLK_SDMMC>;
		clock-names = "biu", "ciu";
		fifo-depth = <0x100>;
		interrupts = <GIC_SPI 4 IRQ_TYPE_LEVEL_HIGH>;
		status = "disabled";
	};

	usb_host0_xhci: usb@ff600000 {
		compatible = "rockchip,rk3328-dwc3";
		reg = <0x0 0xff600000 0x0 0x100000>;
		interrupts = <GIC_SPI 67 IRQ_TYPE_LEVEL_HIGH>;
		snps,dis-enblslpm-quirk;
		snps,phyif-utmi-bits = <16>;
		snps,dis-u2-freeclk-exists-quirk;
		snps,dis-u2-susphy-quirk;
		vbus-supply = <&vcc5v0_host_xhci>;
		status = "okay";
	};

	interrupt-controller@ff811000 {
		compatible = "arm,gic-400";
		#interrupt-cells = <0x3>;
		#address-cells = <0x0>;
		interrupt-controller;
		reg = <0x0 0xff811000 0 0x1000>,
		      <0x0 0xff812000 0 0x2000>,
		      <0x0 0xff814000 0 0x2000>,
		      <0x0 0xff816000 0 0x2000>;
		interrupts = <GIC_PPI 9
		      (GIC_CPU_MASK_SIMPLE(4) | IRQ_TYPE_LEVEL_HIGH)>;
		linux,phandle = <0x1>;
		phandle = <0x1>;
	};

	pinctrl: pinctrl {
		compatible = "rockchip,rk3328-pinctrl";
		rockchip,grf = <0x2a>;
		#address-cells = <0x2>;
		#size-cells = <0x2>;
		ranges;

		gpio0: gpio0@ff210000 {
			compatible = "rockchip,gpio-bank";
			reg = <0x0 0xff210000 0x0 0x100>;
			interrupts = <GIC_SPI 51 IRQ_TYPE_LEVEL_HIGH>;
			clocks = <&cru PCLK_GPIO0>;
			gpio-controller;
			#gpio-cells = <0x2>;
			interrupt-controller;
			#interrupt-cells = <0x2>;
			linux,phandle = <0x57>;
			phandle = <0x57>;
		};

		gpio1: gpio1@ff220000 {
			compatible = "rockchip,gpio-bank";
			reg = <0x0 0xff220000 0x0 0x100>;
			interrupts = <GIC_SPI 52 IRQ_TYPE_LEVEL_HIGH>;
			clocks = <&cru PCLK_GPIO1>;
			gpio-controller;
			#gpio-cells = <0x2>;
			interrupt-controller;
			#interrupt-cells = <0x2>;
			linux,phandle = <0x5c>;
			phandle = <0x5c>;
		};

		gpio2: gpio2@ff230000 {
			compatible = "rockchip,gpio-bank";
			reg = <0x0 0xff230000 0x0 0x100>;
			interrupts = <GIC_SPI 53 IRQ_TYPE_LEVEL_HIGH>;
			clocks = <&cru PCLK_GPIO2>;
			gpio-controller;
			#gpio-cells = <0x2>;
			interrupt-controller;
			#interrupt-cells = <0x2>;
			linux,phandle = <0x36>;
			phandle = <0x36>;
		};

		gpio3: gpio3@ff240000 {
			compatible = "rockchip,gpio-bank";
			reg = <0x0 0xff240000 0x0 0x100>;
			interrupts = <GIC_SPI 54 IRQ_TYPE_LEVEL_HIGH>;
			clocks = <&cru PCLK_GPIO3>;
			gpio-controller;
			#gpio-cells = <0x2>;
			interrupt-controller;
			#interrupt-cells = <0x2>;
		};

		pcfg_pull_up: pcfg-pull-up {
			bias-pull-up;
		};

		pcfg_pull_down: pcfg-pull-down {
			bias-pull-down;
		};

		pcfg_pull_none: pcfg-pull-none {
			bias-disable;
		};

		pcfg_pull_none_2ma: pcfg-pull-none-2ma {
			bias-disable;
			drive-strength = <2>;
		};

		pcfg_pull_up_2ma: pcfg-pull-up-2ma {
			bias-pull-up;
			drive-strength = <2>;
		};

		pcfg_pull_up_4ma: pcfg-pull-up-4ma {
			bias-pull-up;
			drive-strength = <4>;
		};

		pcfg_pull_none_4ma: pcfg-pull-none-4ma {
			bias-disable;
			drive-strength = <4>;
		};

		pcfg_pull_down_4ma: pcfg-pull-down-4ma {
			bias-pull-down;
			drive-strength = <4>;
		};

		pcfg_pull_none_8ma: pcfg-pull-none-8ma {
			bias-disable;
			drive-strength = <8>;
		};

		pcfg_pull_up_8ma: pcfg-pull-up-8ma {
			bias-pull-up;
			drive-strength = <8>;
		};

		pcfg_pull_none_12ma: pcfg-pull-none-12ma {
			bias-disable;
			drive-strength = <12>;
		};

		pcfg_pull_up_12ma: pcfg-pull-up-12ma {
			bias-pull-up;
			drive-strength = <12>;
		};

		pcfg_output_high: pcfg-output-high {
			output-high;
		};

		pcfg_output_low: pcfg-output-low {
			output-low;
		};

		pcfg_input_high: pcfg-input-high {
			bias-pull-up;
			input-enable;
		};

		pcfg_input: pcfg-input {
			input-enable;
		};

		i2c0 {
			i2c0_xfer: i2c0-xfer {
				rockchip,pins =
					<2 24 RK_FUNC_1 &pcfg_pull_none>,
					<2 25 RK_FUNC_1 &pcfg_pull_none>;
			};
		};

		i2c1 {
			i2c1_xfer: i2c1-xfer {
				rockchip,pins =
					<2 4 RK_FUNC_2 &pcfg_pull_none>,
					<2 5 RK_FUNC_2 &pcfg_pull_none>;
			};
		};

		i2c2 {
			i2c2_xfer: i2c2-xfer {
				rockchip,pins =
					<2 13 RK_FUNC_1 &pcfg_pull_none>,
					<2 14 RK_FUNC_1 &pcfg_pull_none>;
			};
		};

		i2c3 {
			i2c3_xfer: i2c3-xfer {
				rockchip,pins =
					<0 5 RK_FUNC_2 &pcfg_pull_none>,
					<0 6 RK_FUNC_2 &pcfg_pull_none>;
			};
			i2c3_gpio: i2c3-gpio {
				rockchip,pins =
					<0 5 RK_FUNC_GPIO &pcfg_pull_none>,
					<0 6 RK_FUNC_GPIO &pcfg_pull_none>;
			};
		};

		hdmi_i2c {
			hdmii2c_xfer: hdmii2c-xfer {
				rockchip,pins =
					<0 5 RK_FUNC_1 &pcfg_pull_none>,
					<0 6 RK_FUNC_1 &pcfg_pull_none>;
			};
		};

		tsadc {

			otp-gpio {
				rockchip,pins = <0x2 0xd 0x0 0x6f>;
				linux,phandle = <0x2b>;
				phandle = <0x2b>;
			};

			otp-out {
				rockchip,pins = <0x2 0xd 0x1 0x6f>;
				linux,phandle = <0x2c>;
				phandle = <0x2c>;
			};
		};

		uart0 {
			uart0_xfer: uart0-xfer {
				rockchip,pins =
					<1 9 RK_FUNC_1 &pcfg_pull_up>,
					<1 8 RK_FUNC_1 &pcfg_pull_none>;
			};

			uart0_cts: uart0-cts {
				rockchip,pins =
					<1 11 RK_FUNC_1 &pcfg_pull_none>;
			};

			uart0_rts: uart0-rts {
				rockchip,pins =
					<1 10 RK_FUNC_1 &pcfg_pull_none>;
			};

			uart0_rts_gpio: uart0-rts-gpio {
				rockchip,pins =
					<1 10 RK_FUNC_GPIO &pcfg_pull_none>;
			};
		};

		uart1 {
			uart1_xfer: uart1-xfer {
				rockchip,pins =
					<3 4 RK_FUNC_4 &pcfg_pull_up>,
					<3 6 RK_FUNC_4 &pcfg_pull_none>;
			};

			uart1_cts: uart1-cts {
				rockchip,pins =
					<3 7 RK_FUNC_4 &pcfg_pull_none>;
			};

			uart1_rts: uart1-rts {
				rockchip,pins =
					<3 5 RK_FUNC_4 &pcfg_pull_none>;
			};

			uart1_rts_gpio: uart1-rts-gpio {
				rockchip,pins =
					<3 5 RK_FUNC_GPIO &pcfg_pull_none>;
			};
		};

		uart2-0 {
			uart2m0_xfer: uart2m0-xfer {
				rockchip,pins =
					<1 0 RK_FUNC_2 &pcfg_pull_up>,
					<1 1 RK_FUNC_2 &pcfg_pull_none>;
			};
		};

		uart2-1 {
			uart2m1_xfer: uart2m1-xfer {
				rockchip,pins =
					<2 0 RK_FUNC_1 &pcfg_pull_up>,
					<2 1 RK_FUNC_1 &pcfg_pull_none>;
			};
		};

		spi0-0 {
			spi0m0_clk: spi0m0-clk {
				rockchip,pins =
					<2 8 RK_FUNC_1 &pcfg_pull_up>;
			};

			spi0m0_cs0: spi0m0-cs0 {
				rockchip,pins =
					<2 11 RK_FUNC_1 &pcfg_pull_up>;
			};

			spi0m0_tx: spi0m0-tx {
				rockchip,pins =
					<2 9 RK_FUNC_1 &pcfg_pull_up>;
			};

			spi0m0_rx: spi0m0-rx {
				rockchip,pins =
					<2 10 RK_FUNC_1 &pcfg_pull_up>;
			};

			spi0m0_cs1: spi0m0-cs1 {
				rockchip,pins =
					<2 12 RK_FUNC_1 &pcfg_pull_up>;
			};
		};

		spi0-1 {
			spi0m1_clk: spi0m1-clk {
				rockchip,pins =
					<3 23 RK_FUNC_2 &pcfg_pull_up>;
			};

			spi0m1_cs0: spi0m1-cs0 {
				rockchip,pins =
					<3 26 RK_FUNC_2 &pcfg_pull_up>;
			};

			spi0m1_tx: spi0m1-tx {
				rockchip,pins =
					<3 25 RK_FUNC_2 &pcfg_pull_up>;
			};

			spi0m1_rx: spi0m1-rx {
				rockchip,pins =
					<3 24 RK_FUNC_2 &pcfg_pull_up>;
			};

			spi0m1_cs1: spi0m1-cs1 {
				rockchip,pins =
					<3 27 RK_FUNC_2 &pcfg_pull_up>;
			};
		};

		spi0-2 {
			spi0m2_clk: spi0m2-clk {
				rockchip,pins =
					<3 0 RK_FUNC_4 &pcfg_pull_up>;
			};

			spi0m2_cs0: spi0m2-cs0 {
				rockchip,pins =
					<3 8 RK_FUNC_3 &pcfg_pull_up>;
			};

			spi0m2_tx: spi0m2-tx {
				rockchip,pins =
					<3 1 RK_FUNC_4 &pcfg_pull_up>;
			};

			spi0m2_rx: spi0m2-rx {
				rockchip,pins =
					<3 2 RK_FUNC_4 &pcfg_pull_up>;
			};
		};

		pdm-0 {

			pdmm0-clk {
				rockchip,pins = <0x2 0x12 0x2 0x6f>;
				linux,phandle = <0x1d>;
				phandle = <0x1d>;
			};

			pdmm0-fsync {
				rockchip,pins = <0x2 0x17 0x2 0x6f>;
				linux,phandle = <0x1e>;
				phandle = <0x1e>;
			};

			pdmm0-sdi0 {
				rockchip,pins = <0x2 0x13 0x2 0x6f>;
				linux,phandle = <0x1f>;
				phandle = <0x1f>;
			};

			pdmm0-sdi1 {
				rockchip,pins = <0x2 0x14 0x2 0x6f>;
				linux,phandle = <0x20>;
				phandle = <0x20>;
			};

			pdmm0-sdi2 {
				rockchip,pins = <0x2 0x15 0x2 0x6f>;
				linux,phandle = <0x21>;
				phandle = <0x21>;
			};

			pdmm0-sdi3 {
				rockchip,pins = <0x2 0x16 0x2 0x6f>;
				linux,phandle = <0x22>;
				phandle = <0x22>;
			};

			pdmm0-sleep {
				rockchip,pins = <0x2 0x12 0x0 0x71 0x2 0x13 0x0 0x71 0x2 0x14 0x0 0x71 0x2 0x15 0x0 0x71 0x2 0x16 0x0 0x71 0x2 0x17 0x0 0x71>;
				linux,phandle = <0x23>;
				phandle = <0x23>;
			};
		};

		i2s1 {
			i2s1_mclk: i2s1-mclk {
				rockchip,pins =
					<2 15 RK_FUNC_1 &pcfg_pull_none>;
			};

			i2s1_sclk: i2s1-sclk {
				rockchip,pins =
					<2 18 RK_FUNC_1 &pcfg_pull_none>;
			};

			i2s1_lrckrx: i2s1-lrckrx {
				rockchip,pins =
					<2 16 RK_FUNC_1 &pcfg_pull_none>;
			};

			i2s1_lrcktx: i2s1-lrcktx {
				rockchip,pins =
					<2 17 RK_FUNC_1 &pcfg_pull_none>;
			};

			i2s1_sdi: i2s1-sdi {
				rockchip,pins =
					<2 19 RK_FUNC_1 &pcfg_pull_none>;
			};

			i2s1_sdo: i2s1-sdo {
				rockchip,pins =
					<2 23 RK_FUNC_1 &pcfg_pull_none>;
			};

			i2s1_sdio1: i2s1-sdio1 {
				rockchip,pins =
					<2 20 RK_FUNC_1 &pcfg_pull_none>;
			};

			i2s1_sdio2: i2s1-sdio2 {
				rockchip,pins =
					<2 21 RK_FUNC_1 &pcfg_pull_none>;
			};

			i2s1_sdio3: i2s1-sdio3 {
				rockchip,pins =
					<2 22 RK_FUNC_1 &pcfg_pull_none>;
			};

			i2s1_sleep: i2s1-sleep {
				rockchip,pins =
					<2 15 RK_FUNC_GPIO &pcfg_input_high>,
					<2 16 RK_FUNC_GPIO &pcfg_input_high>,
					<2 17 RK_FUNC_GPIO &pcfg_input_high>,
					<2 18 RK_FUNC_GPIO &pcfg_input_high>,
					<2 19 RK_FUNC_GPIO &pcfg_input_high>,
					<2 20 RK_FUNC_GPIO &pcfg_input_high>,
					<2 21 RK_FUNC_GPIO &pcfg_input_high>,
					<2 22 RK_FUNC_GPIO &pcfg_input_high>,
					<2 23 RK_FUNC_GPIO &pcfg_input_high>;
			};
		};

		i2s2-0 {
			i2s2m0_mclk: i2s2m0-mclk {
				rockchip,pins =
					<1 21 RK_FUNC_1 &pcfg_pull_none>;
			};

			i2s2m0_sclk: i2s2m0-sclk {
				rockchip,pins =
					<1 22 RK_FUNC_1 &pcfg_pull_none>;
			};

			i2s2m0_lrckrx: i2s2m0-lrckrx {
				rockchip,pins =
					<1 26 RK_FUNC_1 &pcfg_pull_none>;
			};

			i2s2m0_lrcktx: i2s2m0-lrcktx {
				rockchip,pins =
					<1 23 RK_FUNC_1 &pcfg_pull_none>;
			};

			i2s2m0_sdi: i2s2m0-sdi {
				rockchip,pins =
					<1 24 RK_FUNC_1 &pcfg_pull_none>;
			};

			i2s2m0_sdo: i2s2m0-sdo {
				rockchip,pins =
					<1 25 RK_FUNC_1 &pcfg_pull_none>;
			};

			i2s2m0_sleep: i2s2m0-sleep {
				rockchip,pins =
					<1 21 RK_FUNC_GPIO &pcfg_input_high>,
					<1 22 RK_FUNC_GPIO &pcfg_input_high>,
					<1 26 RK_FUNC_GPIO &pcfg_input_high>,
					<1 23 RK_FUNC_GPIO &pcfg_input_high>,
					<1 24 RK_FUNC_GPIO &pcfg_input_high>,
					<1 25 RK_FUNC_GPIO &pcfg_input_high>;
			};
		};

		i2s2-1 {
			i2s2m1_mclk: i2s2m1-mclk {
				rockchip,pins =
					<1 21 RK_FUNC_1 &pcfg_pull_none>;
			};

			i2s2m1_sclk: i2s2m1-sclk {
				rockchip,pins =
					<3 0 RK_FUNC_6 &pcfg_pull_none>;
			};

			i2s2m1_lrckrx: i2sm1-lrckrx {
				rockchip,pins =
					<3 8 RK_FUNC_6 &pcfg_pull_none>;
			};

			i2s2m1_lrcktx: i2s2m1-lrcktx {
				rockchip,pins =
					<3 8 RK_FUNC_4 &pcfg_pull_none>;
			};

			i2s2m1_sdi: i2s2m1-sdi {
				rockchip,pins =
					<3 2 RK_FUNC_6 &pcfg_pull_none>;
			};

			i2s2m1_sdo: i2s2m1-sdo {
				rockchip,pins =
					<3 1 RK_FUNC_6 &pcfg_pull_none>;
			};

			i2s2m1_sleep: i2s2m1-sleep {
				rockchip,pins =
					<1 21 RK_FUNC_GPIO &pcfg_input_high>,
					<3 0 RK_FUNC_GPIO &pcfg_input_high>,
					<3 8 RK_FUNC_GPIO &pcfg_input_high>,
					<3 2 RK_FUNC_GPIO &pcfg_input_high>,
					<3 1 RK_FUNC_GPIO &pcfg_input_high>;
			};
		};

		spdif-0 {
			spdifm0_tx: spdifm0-tx {
				rockchip,pins =
					<0 27 RK_FUNC_1 &pcfg_pull_none>;
			};
		};

		spdif-1 {
			spdifm1_tx: spdifm1-tx {
				rockchip,pins =
					<2 17 RK_FUNC_2 &pcfg_pull_none>;
			};
		};

		spdif-2 {
			spdifm2_tx: spdifm2-tx {
				rockchip,pins =
					<0 2 RK_FUNC_2 &pcfg_pull_none>;
			};
		};

		sdmmc0-0 {
			sdmmc0m0_pwren: sdmmc0m0-pwren {
				rockchip,pins =
					<2 7 RK_FUNC_1 &pcfg_pull_up_4ma>;
			};

			sdmmc0m0_gpio: sdmmc0m0-gpio {
				rockchip,pins =
					<2 7 RK_FUNC_GPIO &pcfg_pull_up_4ma>;
			};
		};

		sdmmc0-1 {
			sdmmc0m1_pwren: sdmmc0m1-pwren {
				rockchip,pins =
					<0 30 RK_FUNC_3 &pcfg_pull_up_4ma>;
			};

			sdmmc0m1_gpio: sdmmc0m1-gpio {
				rockchip,pins =
					<0 30 RK_FUNC_GPIO &pcfg_pull_up_4ma>;
			};
		};

		sdmmc0 {
			sdmmc0_clk: sdmmc0-clk {
				rockchip,pins =
					<1 6 RK_FUNC_1 &pcfg_pull_none_4ma>;
			};

			sdmmc0_cmd: sdmmc0-cmd {
				rockchip,pins =
					<1 4 RK_FUNC_1 &pcfg_pull_up_4ma>;
			};

			sdmmc0_dectn: sdmmc0-dectn {
				rockchip,pins =
					<1 5 RK_FUNC_1 &pcfg_pull_up_4ma>;
			};

			sdmmc0_wrprt: sdmmc0-wrprt {
				rockchip,pins =
					<1 7 RK_FUNC_1 &pcfg_pull_up_4ma>;
			};

			sdmmc0_bus1: sdmmc0-bus1 {
				rockchip,pins =
					<1 0 RK_FUNC_1 &pcfg_pull_up_4ma>;
			};

			sdmmc0_bus4: sdmmc0-bus4 {
				rockchip,pins =
					<1 0 RK_FUNC_1 &pcfg_pull_up_4ma>,
					<1 1 RK_FUNC_1 &pcfg_pull_up_4ma>,
					<1 2 RK_FUNC_1 &pcfg_pull_up_4ma>,
					<1 3 RK_FUNC_1 &pcfg_pull_up_4ma>;
			};

			sdmmc0_gpio: sdmmc0-gpio {
				rockchip,pins =
					<1 6 RK_FUNC_GPIO &pcfg_pull_up_4ma>,
					<1 4 RK_FUNC_GPIO &pcfg_pull_up_4ma>,
					<1 5 RK_FUNC_GPIO &pcfg_pull_up_4ma>,
					<1 7 RK_FUNC_GPIO &pcfg_pull_up_4ma>,
					<1 3 RK_FUNC_GPIO &pcfg_pull_up_4ma>,
					<1 2 RK_FUNC_GPIO &pcfg_pull_up_4ma>,
					<1 1 RK_FUNC_GPIO &pcfg_pull_up_4ma>,
					<1 0 RK_FUNC_GPIO &pcfg_pull_up_4ma>;
			};
		};

		sdmmc0ext {
			sdmmc0ext_clk: sdmmc0ext-clk {
				rockchip,pins =
					<3 2 RK_FUNC_3 &pcfg_pull_none_4ma>;
			};

			sdmmc0ext_cmd: sdmmc0ext-cmd {
				rockchip,pins =
					<3 0 RK_FUNC_3 &pcfg_pull_up_4ma>;
			};

			sdmmc0ext_wrprt: sdmmc0ext-wrprt {
				rockchip,pins =
					<3 3 RK_FUNC_3 &pcfg_pull_up_4ma>;
			};

			sdmmc0ext_dectn: sdmmc0ext-dectn {
				rockchip,pins =
					<3 1 RK_FUNC_3 &pcfg_pull_up_4ma>;
			};

			sdmmc0ext_bus1: sdmmc0ext-bus1 {
				rockchip,pins =
					<3 4 RK_FUNC_3 &pcfg_pull_up_4ma>;
			};

			sdmmc0ext_bus4: sdmmc0ext-bus4 {
				rockchip,pins =
					<3 4 RK_FUNC_3 &pcfg_pull_up_4ma>,
					<3 5 RK_FUNC_3 &pcfg_pull_up_4ma>,
					<3 6 RK_FUNC_3 &pcfg_pull_up_4ma>,
					<3 7 RK_FUNC_3 &pcfg_pull_up_4ma>;
			};

			sdmmc0ext_gpio: sdmmc0ext-gpio {
				rockchip,pins =
					<3 0 RK_FUNC_GPIO &pcfg_pull_up_4ma>,
					<3 1 RK_FUNC_GPIO &pcfg_pull_up_4ma>,
					<3 2 RK_FUNC_GPIO &pcfg_pull_up_4ma>,
					<3 3 RK_FUNC_GPIO &pcfg_pull_up_4ma>,
					<3 4 RK_FUNC_GPIO &pcfg_pull_up_4ma>,
					<3 5 RK_FUNC_GPIO &pcfg_pull_up_4ma>,
					<3 6 RK_FUNC_GPIO &pcfg_pull_up_4ma>,
					<3 7 RK_FUNC_GPIO &pcfg_pull_up_4ma>;
			};
		};

		sdmmc1 {
			sdmmc1_clk: sdmmc1-clk {
				rockchip,pins =
					<1 12 RK_FUNC_1 &pcfg_pull_none_8ma>;
			};

			sdmmc1_cmd: sdmmc1-cmd {
				rockchip,pins =
					<1 13 RK_FUNC_1 &pcfg_pull_up_8ma>;
			};

			sdmmc1_pwren: sdmmc1-pwren {
				rockchip,pins =
					<1 18 RK_FUNC_1 &pcfg_pull_up_8ma>;
			};

			sdmmc1_wrprt: sdmmc1-wrprt {
				rockchip,pins =
					<1 20 RK_FUNC_1 &pcfg_pull_up_8ma>;
			};

			sdmmc1_dectn: sdmmc1-dectn {
				rockchip,pins =
					<1 19 RK_FUNC_1 &pcfg_pull_up_8ma>;
			};

			sdmmc1_bus1: sdmmc1-bus1 {
				rockchip,pins =
					<1 14 RK_FUNC_1 &pcfg_pull_up_8ma>;
			};

			sdmmc1_bus4: sdmmc1-bus4 {
				rockchip,pins =
					<1 12 RK_FUNC_1 &pcfg_pull_up_8ma>,
					<1 13 RK_FUNC_1 &pcfg_pull_up_8ma>,
					<1 16 RK_FUNC_1 &pcfg_pull_up_8ma>,
					<1 17 RK_FUNC_1 &pcfg_pull_up_8ma>;
			};

			sdmmc1_gpio: sdmmc1-gpio {
				rockchip,pins =
					<1 12 RK_FUNC_GPIO &pcfg_pull_up_4ma>,
					<1 13 RK_FUNC_GPIO &pcfg_pull_up_4ma>,
					<1 14 RK_FUNC_GPIO &pcfg_pull_up_4ma>,
					<1 15 RK_FUNC_GPIO &pcfg_pull_up_4ma>,
					<1 16 RK_FUNC_GPIO &pcfg_pull_up_4ma>,
					<1 17 RK_FUNC_GPIO &pcfg_pull_up_4ma>,
					<1 18 RK_FUNC_GPIO &pcfg_pull_up_4ma>,
					<1 19 RK_FUNC_GPIO &pcfg_pull_up_4ma>,
					<1 20 RK_FUNC_GPIO &pcfg_pull_up_4ma>;
			};
		};

		emmc {
			emmc_clk: emmc-clk {
				rockchip,pins =
					<3 21 RK_FUNC_2 &pcfg_pull_none_12ma>;
			};

			emmc_cmd: emmc-cmd {
				rockchip,pins =
					<3 19 RK_FUNC_2 &pcfg_pull_up_12ma>;
			};

			emmc_pwren: emmc-pwren {
				rockchip,pins =
					<3 22 RK_FUNC_2 &pcfg_pull_none>;
			};

			emmc_rstnout: emmc-rstnout {
				rockchip,pins =
					<3 20 RK_FUNC_2 &pcfg_pull_none>;
			};

			emmc_bus1: emmc-bus1 {
				rockchip,pins =
					<0 7 RK_FUNC_2 &pcfg_pull_up_12ma>;
			};

			emmc_bus4: emmc-bus4 {
				rockchip,pins =
					<0 7 RK_FUNC_2 &pcfg_pull_up_12ma>,
					<2 28 RK_FUNC_2 &pcfg_pull_up_12ma>,
					<2 29 RK_FUNC_2 &pcfg_pull_up_12ma>,
					<2 30 RK_FUNC_2 &pcfg_pull_up_12ma>;
			};

			emmc_bus8: emmc-bus8 {
				rockchip,pins =
					<0 7 RK_FUNC_2 &pcfg_pull_up_12ma>,
					<2 28 RK_FUNC_2 &pcfg_pull_up_12ma>,
					<2 29 RK_FUNC_2 &pcfg_pull_up_12ma>,
					<2 30 RK_FUNC_2 &pcfg_pull_up_12ma>,
					<2 31 RK_FUNC_2 &pcfg_pull_up_12ma>,
					<3 16 RK_FUNC_2 &pcfg_pull_up_12ma>,
					<3 17 RK_FUNC_2 &pcfg_pull_up_12ma>,
					<3 18 RK_FUNC_2 &pcfg_pull_up_12ma>;
			};
		};

		pwm0 {
			pwm0_pin: pwm0-pin {
				rockchip,pins =
					<2 4 RK_FUNC_1 &pcfg_pull_none>;
			};
		};

		pwm1 {
			pwm1_pin: pwm1-pin {
				rockchip,pins =
					<2 5 RK_FUNC_1 &pcfg_pull_none>;
			};
		};

		pwm2 {
			pwm2_pin: pwm2-pin {
				rockchip,pins =
					<2 6 RK_FUNC_1 &pcfg_pull_none>;
			};
		};

		pwmir {
			pwmir_pin: pwmir-pin {
				rockchip,pins =
					<2 2 RK_FUNC_1 &pcfg_pull_none>;
			};
		};

		gmac-0 {
			rgmiim0_pins: rgmiim0-pins {
				rockchip,pins =
					/* mac_txclk */
					<0 8 RK_FUNC_1 &pcfg_pull_none_12ma>,
					/* mac_rxclk */
					<0 10 RK_FUNC_1 &pcfg_pull_none>,
					/* mac_mdio */
					<0 11 RK_FUNC_1 &pcfg_pull_none>,
					/* mac_txen */
					<0 12 RK_FUNC_1 &pcfg_pull_none_12ma>,
					/* mac_clk */
					<0 24 RK_FUNC_1 &pcfg_pull_none>,
					/* mac_rxdv */
					<0 25 RK_FUNC_1 &pcfg_pull_none>,
					/* mac_mdc */
					<0 19 RK_FUNC_1 &pcfg_pull_none>,
					/* mac_rxd1 */
					<0 14 RK_FUNC_1 &pcfg_pull_none>,
					/* mac_rxd0 */
					<0 15 RK_FUNC_1 &pcfg_pull_none>,
					/* mac_txd1 */
					<0 16 RK_FUNC_1 &pcfg_pull_none_12ma>,
					/* mac_txd0 */
					<0 17 RK_FUNC_1 &pcfg_pull_none_12ma>,
					/* mac_rxd3 */
					<0 20 RK_FUNC_1 &pcfg_pull_none>,
					/* mac_rxd2 */
					<0 21 RK_FUNC_1 &pcfg_pull_none>,
					/* mac_txd3 */
					<0 23 RK_FUNC_1 &pcfg_pull_none_12ma>,
					/* mac_txd2 */
					<0 22 RK_FUNC_1 &pcfg_pull_none_12ma>;
			};

			rmiim0_pins: rmiim0-pins {
				rockchip,pins =
					/* mac_mdio */
					<0 11 RK_FUNC_1 &pcfg_pull_none>,
					/* mac_txen */
					<0 12 RK_FUNC_1 &pcfg_pull_none_12ma>,
					/* mac_clk */
					<0 24 RK_FUNC_1 &pcfg_pull_none>,
					/* mac_rxer */
					<0 13 RK_FUNC_1 &pcfg_pull_none>,
					/* mac_rxdv */
					<0 25 RK_FUNC_1 &pcfg_pull_none>,
					/* mac_mdc */
					<0 19 RK_FUNC_1 &pcfg_pull_none>,
					/* mac_rxd1 */
					<0 14 RK_FUNC_1 &pcfg_pull_none>,
					/* mac_rxd0 */
					<0 15 RK_FUNC_1 &pcfg_pull_none>,
					/* mac_txd1 */
					<0 16 RK_FUNC_1 &pcfg_pull_none_12ma>,
					/* mac_txd0 */
					<0 17 RK_FUNC_1 &pcfg_pull_none_12ma>;
			};
		};

		gmac-1 {
			rgmiim1_pins: rgmiim1-pins {
				rockchip,pins =
					/* mac_txclk */
					<1 12 RK_FUNC_2 &pcfg_pull_none_12ma>,
					/* mac_rxclk */
					<1 13 RK_FUNC_2 &pcfg_pull_none_2ma>,
					/* mac_mdio */
					<1 19 RK_FUNC_2 &pcfg_pull_none_2ma>,
					/* mac_txen */
					<1 25 RK_FUNC_2 &pcfg_pull_none_12ma>,
					/* mac_clk */
					<1 21 RK_FUNC_2 &pcfg_pull_none_2ma>,
					/* mac_rxdv */
					<1 22 RK_FUNC_2 &pcfg_pull_none_2ma>,
					/* mac_mdc */
					<1 23 RK_FUNC_2 &pcfg_pull_none_2ma>,
					/* mac_rxd1 */
					<1 10 RK_FUNC_2 &pcfg_pull_none_2ma>,
					/* mac_rxd0 */
					<1 11 RK_FUNC_2 &pcfg_pull_none_2ma>,
					/* mac_txd1 */
					<1 8 RK_FUNC_2 &pcfg_pull_none_12ma>,
					/* mac_txd0 */
					<1 9 RK_FUNC_2 &pcfg_pull_none_12ma>,
					/* mac_rxd3 */
					<1 14 RK_FUNC_2 &pcfg_pull_none_2ma>,
					/* mac_rxd2 */
					<1 15 RK_FUNC_2 &pcfg_pull_none_2ma>,
					/* mac_txd3 */
					<1 16 RK_FUNC_2 &pcfg_pull_none_12ma>,
					/* mac_txd2 */
					<1 17 RK_FUNC_2 &pcfg_pull_none_12ma>,

					/* mac_txclk */
					<0 8 RK_FUNC_1 &pcfg_pull_none>,
					/* mac_txen */
					<0 12 RK_FUNC_1 &pcfg_pull_none>,
					/* mac_clk */
					<0 24 RK_FUNC_1 &pcfg_pull_none>,
					/* mac_txd1 */
					<0 16 RK_FUNC_1 &pcfg_pull_none>,
					/* mac_txd0 */
					<0 17 RK_FUNC_1 &pcfg_pull_none>,
					/* mac_txd3 */
					<0 23 RK_FUNC_1 &pcfg_pull_none>,
					/* mac_txd2 */
					<0 22 RK_FUNC_1 &pcfg_pull_none>;
			};

			rmiim1_pins: rmiim1-pins {
				rockchip,pins =
					/* mac_mdio */
					<1 19 RK_FUNC_2 &pcfg_pull_none_2ma>,
					/* mac_txen */
					<1 25 RK_FUNC_2 &pcfg_pull_none_12ma>,
					/* mac_clk */
					<1 21 RK_FUNC_2 &pcfg_pull_none_2ma>,
					/* mac_rxer */
					<1 24 RK_FUNC_2 &pcfg_pull_none_2ma>,
					/* mac_rxdv */
					<1 22 RK_FUNC_2 &pcfg_pull_none_2ma>,
					/* mac_mdc */
					<1 23 RK_FUNC_2 &pcfg_pull_none_2ma>,
					/* mac_rxd1 */
					<1 10 RK_FUNC_2 &pcfg_pull_none_2ma>,
					/* mac_rxd0 */
					<1 11 RK_FUNC_2 &pcfg_pull_none_2ma>,
					/* mac_txd1 */
					<1 8 RK_FUNC_2 &pcfg_pull_none_12ma>,
					/* mac_txd0 */
					<1 9 RK_FUNC_2 &pcfg_pull_none_12ma>,

					/* mac_mdio */
					<0 11 RK_FUNC_1 &pcfg_pull_none>,
					/* mac_txen */
					<0 12 RK_FUNC_1 &pcfg_pull_none>,
					/* mac_clk */
					<0 24 RK_FUNC_1 &pcfg_pull_none>,
					/* mac_mdc */
					<0 19 RK_FUNC_1 &pcfg_pull_none>,
					/* mac_txd1 */
					<0 16 RK_FUNC_1 &pcfg_pull_none>,
					/* mac_txd0 */
					<0 17 RK_FUNC_1 &pcfg_pull_none>;
			};
		};

		gmac2phy {
			fephyled_speed100: fephyled-speed100 {
				rockchip,pins =
					<0 31 RK_FUNC_1 &pcfg_pull_none>;
			};

			fephyled_speed10: fephyled-speed10 {
				rockchip,pins =
					<0 30 RK_FUNC_1 &pcfg_pull_none>;
			};

			fephyled_duplex: fephyled-duplex {
				rockchip,pins =
					<0 30 RK_FUNC_2 &pcfg_pull_none>;
			};

			fephyled_rxm0: fephyled-rxm0 {
				rockchip,pins =
					<0 29 RK_FUNC_1 &pcfg_pull_none>;
			};

			fephyled_txm0: fephyled-txm0 {
				rockchip,pins =
					<0 29 RK_FUNC_2 &pcfg_pull_none>;
			};

			fephyled_linkm0: fephyled-linkm0 {
				rockchip,pins =
					<0 28 RK_FUNC_1 &pcfg_pull_none>;
			};

			fephyled_rxm1: fephyled-rxm1 {
				rockchip,pins =
					<2 25 RK_FUNC_2 &pcfg_pull_none>;
			};

			fephyled_txm1: fephyled-txm1 {
				rockchip,pins =
					<2 25 RK_FUNC_3 &pcfg_pull_none>;
			};

			fephyled_linkm1: fephyled-linkm1 {
				rockchip,pins =
					<2 24 RK_FUNC_2 &pcfg_pull_none>;
			};
		};

		tsadc_pin {
			tsadc_int: tsadc-int {
				rockchip,pins =
					<2 13 RK_FUNC_2 &pcfg_pull_none>;
			};
			tsadc_gpio: tsadc-gpio {
				rockchip,pins =
					<2 13 RK_FUNC_GPIO &pcfg_pull_none>;
			};
		};

		hdmi_pin {
			hdmi_cec: hdmi-cec {
				rockchip,pins =
					<0 3 RK_FUNC_1 &pcfg_pull_none>;
			};

			hdmi_hpd: hdmi-hpd {
				rockchip,pins =
					<0 4 RK_FUNC_1 &pcfg_pull_down>;
			};
		};

		cif-0 {
			dvp_d2d9_m0:dvp-d2d9-m0 {
				rockchip,pins =
					/* cif_d0 */
					<3 4 RK_FUNC_2 &pcfg_pull_none>,
					/* cif_d1 */
					<3 5 RK_FUNC_2 &pcfg_pull_none>,
					/* cif_d2 */
					<3 6 RK_FUNC_2 &pcfg_pull_none>,
					/* cif_d3 */
					<3 7 RK_FUNC_2 &pcfg_pull_none>,
					/* cif_d4 */
					<3 8 RK_FUNC_2 &pcfg_pull_none>,
					/* cif_d5m0 */
					<3 9 RK_FUNC_2 &pcfg_pull_none>,
					/* cif_d6m0 */
					<3 10 RK_FUNC_2 &pcfg_pull_none>,
					/* cif_d7m0 */
					<3 11 RK_FUNC_2 &pcfg_pull_none>,
					/* cif_href */
					<3 1 RK_FUNC_2 &pcfg_pull_none>,
					/* cif_vsync */
					<3 0 RK_FUNC_2 &pcfg_pull_none>,
					/* cif_clkoutm0 */
					<3 3 RK_FUNC_2 &pcfg_pull_none>,
					/* cif_clkin */
					<3 2 RK_FUNC_2 &pcfg_pull_none>;
			};
		};

		cif-1 {
			dvp_d2d9_m1:dvp-d2d9-m1 {
				rockchip,pins =
					/* cif_d0 */
					<3 4 RK_FUNC_2 &pcfg_pull_none>,
					/* cif_d1 */
					<3 5 RK_FUNC_2 &pcfg_pull_none>,
					/* cif_d2 */
					<3 6 RK_FUNC_2 &pcfg_pull_none>,
					/* cif_d3 */
					<3 7 RK_FUNC_2 &pcfg_pull_none>,
					/* cif_d4 */
					<3 8 RK_FUNC_2 &pcfg_pull_none>,
					/* cif_d5m1 */
					<2 16 RK_FUNC_4 &pcfg_pull_none>,
					/* cif_d6m1 */
					<2 17 RK_FUNC_4 &pcfg_pull_none>,
					/* cif_d7m1 */
					<2 18 RK_FUNC_4 &pcfg_pull_none>,
					/* cif_href */
					<3 1 RK_FUNC_2 &pcfg_pull_none>,
					/* cif_vsync */
					<3 0 RK_FUNC_2 &pcfg_pull_none>,
					/* cif_clkoutm1 */
					<2 15 RK_FUNC_4 &pcfg_pull_none>,
					/* cif_clkin */
					<3 2 RK_FUNC_2 &pcfg_pull_none>;
			};
		};

		pmic {

			pmic_int_l: pmic-int-l {
				rockchip,pins =
					<2 RK_PA6 RK_FUNC_GPIO &pcfg_pull_up>;	/* gpio2_a6 */
			};
		};

		sdio-pwrseq {

			wifi-enable-h {
				rockchip,pins = <0x1 0x12 0x0 0x6f>;
				linux,phandle = <0x7b>;
				phandle = <0x7b>;
			};
		};
	};

	chosen {
		stdout-path = "/serial@ff130000";
	};

	leds {
		compatible = "gpio-leds";

		standby-led {
			linux,default-trigger = "disk-activity";
			gpios = <0x7a 0x0 0x1>;
			default-state = "on";
		};

		power-led {
			gpios = <0x7a 0x1 0x1>;
			default-state = "on";
		};
	};

	switches {
		compatible = "gpio-leds";

		usb-switch {
			linux,default-trigger = "none";
			gpios = <0x57 0x2 0x1>;
			mode = <0x23>;
			default-state = "on";
		};
	};

	fiq-debugger {
		compatible = "rockchip,fiq-debugger";
		rockchip,serial-id = <0x2>;
		rockchip,signal-irq = <0x9f>;
		rockchip,wake-irq = <0x0>;
		rockchip,irq-mode-enable = <0x0>;
		rockchip,baudrate = <0x16e360>;
		interrupts = <0x0 0x7f 0x8>;
		status = "okay";
	};

	gmac_clkin: external-gmac-clock {
		compatible = "fixed-clock";
		clock-frequency = <125000000>;
		clock-output-names = "gmac_clkin";
		#clock-cells = <0>;
	};

	sdio-pwrseq {
		compatible = "mmc-pwrseq-simple";
		pinctrl-names = "default";
		pinctrl-0 = <0x7b>;
		reset-gpios = <0x5c 0x12 0x1>;
		linux,phandle = <0x62>;
		phandle = <0x62>;
	};

	dummy-codec {
		compatible = "linux,snd-soc-dummy";
		#sound-dai-cells = <0x0>;
		linux,phandle = <0x80>;
		phandle = <0x80>;
	};

	hdmi-sound {
		compatible = "simple-audio-card";
		simple-audio-card,format = "i2s";
		simple-audio-card,mclk-fs = <0x100>;
		simple-audio-card,name = "HDMI";

		simple-audio-card,cpu {
			sound-dai = <0x7c>;
		};

		simple-audio-card,codec {
			sound-dai = <0x7d>;
		};
	};

	sound {
		compatible = "simple-audio-card";
		simple-audio-card,mclk-fs = <0x100>;
		simple-audio-card,name = "I2S";

		simple-audio-card,dai-link@0 {
			format = "i2s";

			cpu {
				sound-dai = <0x7e>;
			};

			codec {
				sound-dai = <0x7f>;
			};
		};

		simple-audio-card,dai-link@1 {
			format = "i2s";

			cpu {
				sound-dai = <0x7e>;
			};

			codec {
				sound-dai = <0x80>;
			};
		};
	};

	spdif-sound {
		compatible = "simple-audio-card";
		simple-audio-card,name = "SPDIF";

		simple-audio-card,cpu {
			sound-dai = <0x81>;
		};

		simple-audio-card,codec {
			sound-dai = <0x82>;
		};
	};

	spdif-out {
		compatible = "linux,spdif-dit";
		#sound-dai-cells = <0x0>;
		linux,phandle = <0x82>;
		phandle = <0x82>;
	};

	vcc_phy: vcc-phy-regulator {
		compatible = "regulator-fixed";
		regulator-name = "vcc_phy";
		regulator-always-on;
		regulator-boot-on;
	};
	
	vcc3v3_sdmmc: sdmmc-pwren {
		compatible = "regulator-fixed";
		regulator-name = "vcc3v3";
		gpio = <&gpio0 30 GPIO_ACTIVE_LOW>;
		regulator-always-on;
		regulator-boot-on;
	};
	
	vcc5v0_otg: vcc5v0-otg-drv {
		compatible = "regulator-fixed";
		enable-active-high;
		regulator-name = "vcc5v0_otg";
		gpio = <&gpio0 27 GPIO_ACTIVE_HIGH>;
		regulator-min-microvolt = <5000000>;
		regulator-max-microvolt = <5000000>;
	};

	vcc5v0_host_xhci: vcc5v0-host-xhci-drv {
		compatible = "regulator-fixed";
		enable-active-high;
		regulator-name = "vcc5v0_host_xhci";
		gpio = <&gpio0 0 GPIO_ACTIVE_HIGH>;
		regulator-min-microvolt = <5000000>;
		regulator-max-microvolt = <5000000>;
	};

	sdmmc-regulator {
		compatible = "regulator-fixed";
		gpio = <0x57 0x1e 0x1>;
		pinctrl-names = "default";
		pinctrl-0 = <0x83>;
		regulator-name = "vcc_sd";
		regulator-min-microvolt = <0x325aa0>;
		regulator-max-microvolt = <0x325aa0>;
		vin-supply = <0x24>;
		linux,phandle = <0x61>;
		phandle = <0x61>;
	};

	vcc-sys {
		compatible = "regulator-fixed";
		regulator-name = "vcc_sys";
		regulator-always-on;
		regulator-boot-on;
		regulator-min-microvolt = <0x4c4b40>;
		regulator-max-microvolt = <0x4c4b40>;
	};

	wireless-wlan {
		compatible = "wlan-platdata";
		rockchip,grf = <0x2a>;
		wifi_chip_type = "ap6354";
		sdio_vref = <0x708>;
		WIFI,host_wake_irq = <0x5c 0x13 0x0>;
		status = "disabled";
	};
};

#include "rk3328-sdram-lpddr3-1600.dtsi"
